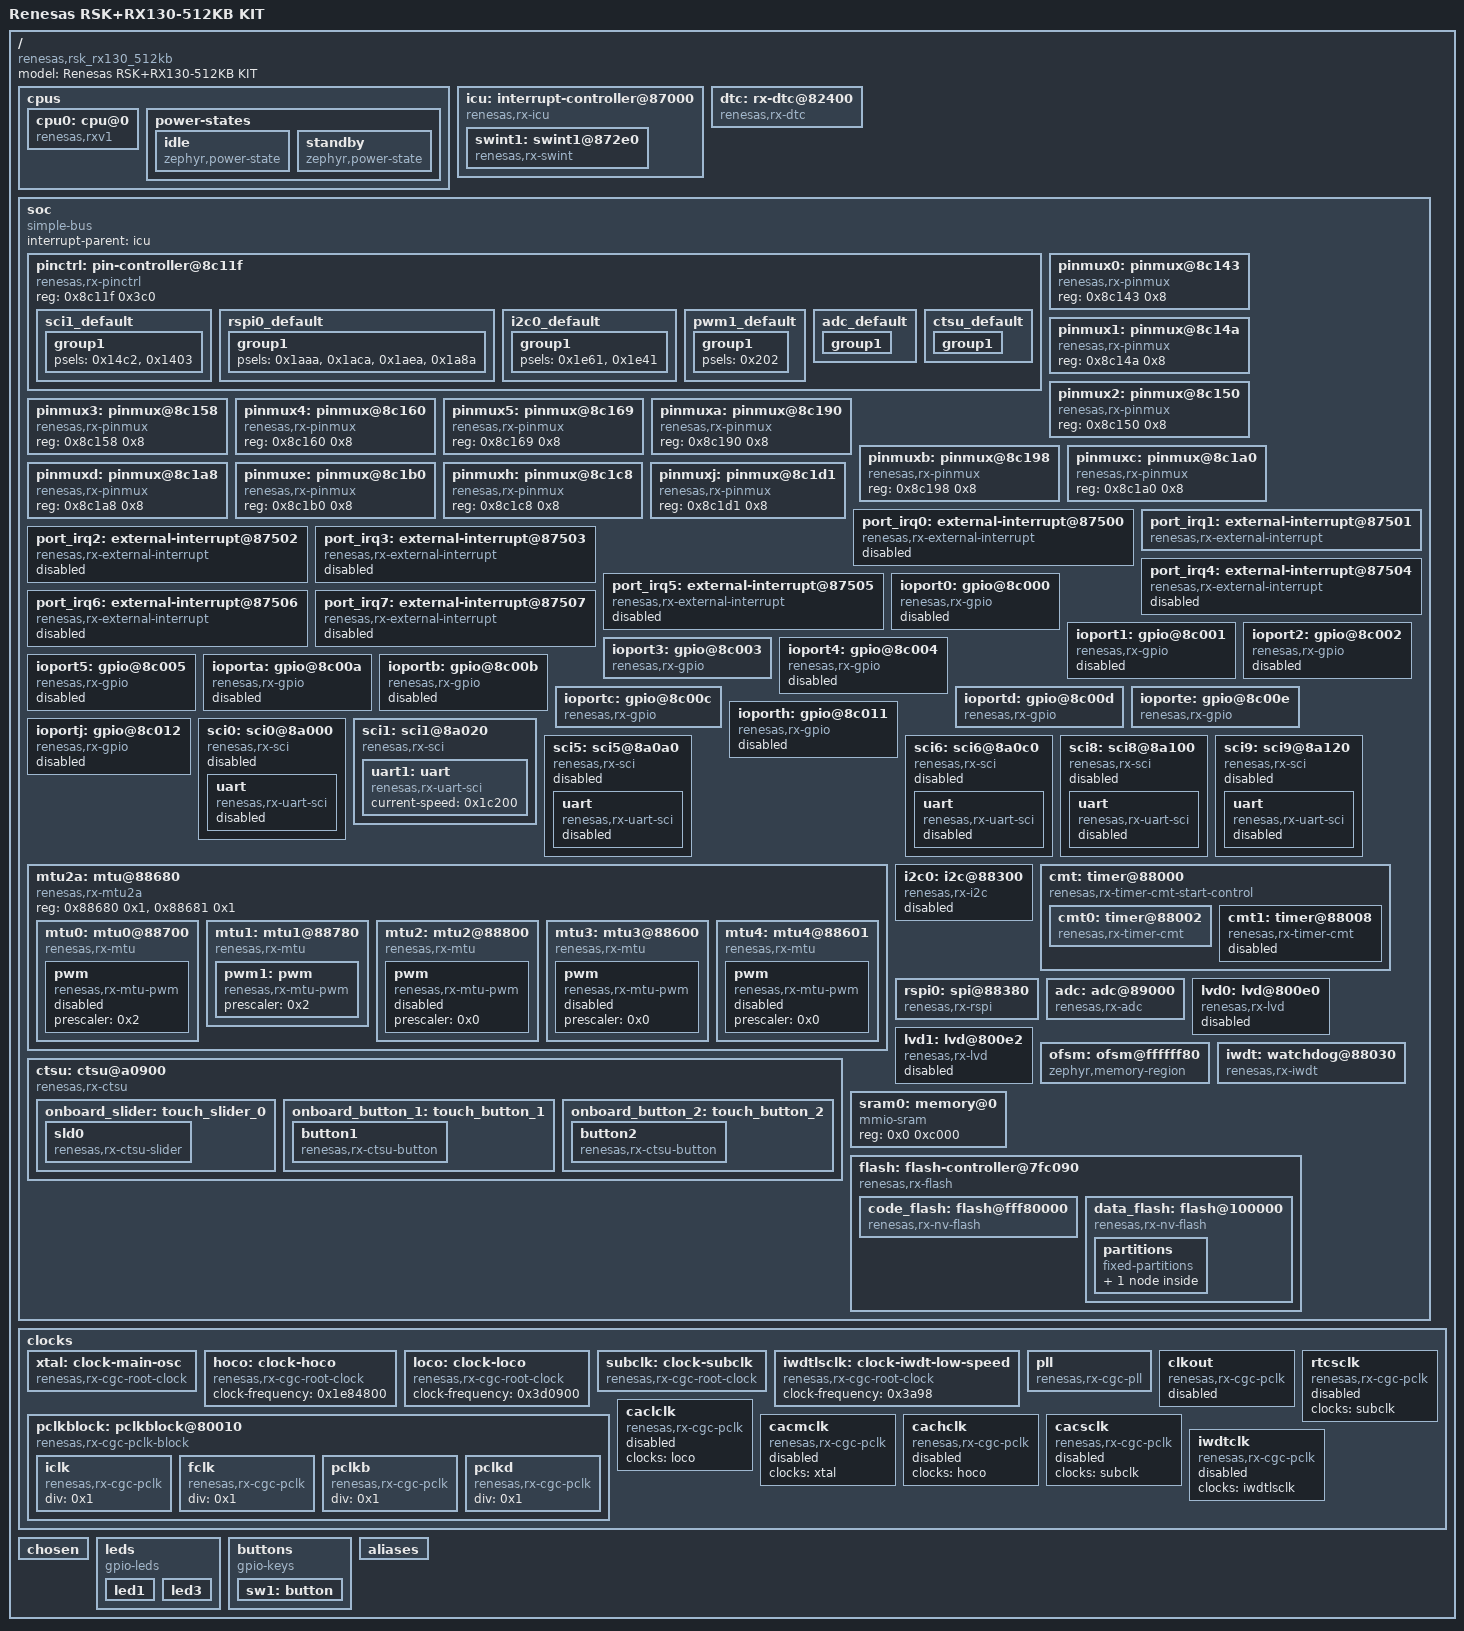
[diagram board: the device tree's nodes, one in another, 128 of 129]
/dts-v1/;

/* node '/' defined in zephyr/dts/rx/renesas/rx130-common.dtsi:16 */
/ {
	#address-cells = < 0x1 >;               /* in zephyr/dts/rx/renesas/rx130-common.dtsi:17 */
	#size-cells = < 0x1 >;                  /* in zephyr/dts/rx/renesas/rx130-common.dtsi:18 */
	model = "Renesas RSK+RX130-512KB KIT";  /* in zephyr/boards/renesas/rsk_rx130/rsk_rx130.dts:16 */
	compatible = "renesas,rsk_rx130_512kb"; /* in zephyr/boards/renesas/rsk_rx130/rsk_rx130.dts:17 */

	/* node '/cpus' defined in zephyr/dts/rx/renesas/rx130-common.dtsi:20 */
	cpus {
		#address-cells = < 0x1 >; /* in zephyr/dts/rx/renesas/rx130-common.dtsi:21 */
		#size-cells = < 0x0 >;    /* in zephyr/dts/rx/renesas/rx130-common.dtsi:22 */

		/* node '/cpus/cpu@0' defined in zephyr/dts/rx/renesas/rx130-common.dtsi:24 */
		cpu0: cpu@0 {
			compatible = "renesas,rxv1";           /* in zephyr/dts/rx/renesas/rx130-common.dtsi:25 */
			device_type = "cpu";                   /* in zephyr/dts/rx/renesas/rx130-common.dtsi:26 */
			reg = < 0x0 >;                         /* in zephyr/dts/rx/renesas/rx130-common.dtsi:27 */
			cpu-power-states = < &idle &standby >; /* in zephyr/dts/rx/renesas/rx130-common.dtsi:28 */
			status = "okay";                       /* in zephyr/dts/rx/renesas/rx130-common.dtsi:29 */
		};

		/* node '/cpus/power-states' defined in zephyr/dts/rx/renesas/rx130-common.dtsi:32 */
		power-states {

			/* node '/cpus/power-states/idle' defined in zephyr/dts/rx/renesas/rx130-common.dtsi:33 */
			idle: idle {
				compatible = "zephyr,power-state";    /* in zephyr/dts/rx/renesas/rx130-common.dtsi:34 */
				power-state-name = "suspend-to-idle"; /* in zephyr/dts/rx/renesas/rx130-common.dtsi:35 */
				min-residency-us = < 0x12c >;         /* in zephyr/dts/rx/renesas/rx130-common.dtsi:36 */
				phandle = < 0x1 >;                    /* in zephyr/dts/rx/renesas/rx130-common.dtsi:28 */
			};

			/* node '/cpus/power-states/standby' defined in zephyr/dts/rx/renesas/rx130-common.dtsi:39 */
			standby: standby {
				compatible = "zephyr,power-state"; /* in zephyr/dts/rx/renesas/rx130-common.dtsi:40 */
				power-state-name = "standby";      /* in zephyr/dts/rx/renesas/rx130-common.dtsi:41 */
				min-residency-us = < 0xbb8 >;      /* in zephyr/dts/rx/renesas/rx130-common.dtsi:42 */
				exit-latency-us = < 0x1f4 >;       /* in zephyr/dts/rx/renesas/rx130-common.dtsi:43 */
				phandle = < 0x2 >;                 /* in zephyr/dts/rx/renesas/rx130-common.dtsi:28 */
			};
		};
	};

	/* node '/interrupt-controller@87000' defined in zephyr/dts/rx/renesas/rx130-common.dtsi:48 */
	icu: interrupt-controller@87000 {
		#interrupt-cells = < 0x2 >;    /* in zephyr/dts/rx/renesas/rx130-common.dtsi:49 */
		#address-cells = < 0x1 >;      /* in zephyr/dts/rx/renesas/rx130-common.dtsi:50 */
		#size-cells = < 0x1 >;         /* in zephyr/dts/rx/renesas/rx130-common.dtsi:51 */
		compatible = "renesas,rx-icu"; /* in zephyr/dts/rx/renesas/rx130-common.dtsi:52 */
		interrupt-controller;          /* in zephyr/dts/rx/renesas/rx130-common.dtsi:53 */
		reg = < 0x87000 0xff >,
		      < 0x87200 0x1f >,
		      < 0x87300 0xff >,
		      < 0x872f0 0x2 >,
		      < 0x87500 0xf >,
		      < 0x87510 0x1 >,
		      < 0x87514 0x1 >,
		      < 0x87580 0x1 >,
		      < 0x87581 0x1 >,
		      < 0x87582 0x1 >;         /* in zephyr/dts/rx/renesas/rx130-common.dtsi:54 */
		reg-names = "IR",
		            "IER",
		            "IPR",
		            "FIR",
		            "IRQCR",
		            "IRQFLTE",
		            "IRQFLTC0",
		            "NMISR",
		            "NMIER",
		            "NMICLR";          /* in zephyr/dts/rx/renesas/rx130-common.dtsi:64 */
		phandle = < 0x3 >;             /* in zephyr/dts/rx/renesas/rx130-common.dtsi:71 */

		/* node '/interrupt-controller@87000/swint1@872e0' defined in zephyr/dts/rx/renesas/rx130-common.dtsi:67 */
		swint1: swint1@872e0 {
			compatible = "renesas,rx-swint"; /* in zephyr/dts/rx/renesas/rx130-common.dtsi:68 */
			reg = < 0x872e0 0x1 >;           /* in zephyr/dts/rx/renesas/rx130-common.dtsi:69 */
			interrupts = < 0x1b 0xe >;       /* in zephyr/dts/rx/renesas/rx130-common.dtsi:70 */
			interrupt-parent = < &icu >;     /* in zephyr/dts/rx/renesas/rx130-common.dtsi:71 */
			status = "okay";                 /* in zephyr/dts/rx/renesas/rx130-common.dtsi:72 */
		};
	};

	/* node '/rx-dtc@82400' defined in zephyr/dts/rx/renesas/rx130-common.dtsi:76 */
	dtc: rx-dtc@82400 {
		compatible = "renesas,rx-dtc"; /* in zephyr/dts/rx/renesas/rx130-common.dtsi:77 */
		reg = < 0x82400 0x1 >;         /* in zephyr/dts/rx/renesas/rx130-common.dtsi:78 */
		clocks = < &iclk 0x0 0x1c >;   /* in zephyr/dts/rx/renesas/rx130-common.dtsi:79 */
		status = "okay";               /* in zephyr/dts/rx/renesas/rx130-common.dtsi:80 */
		phandle = < 0x1b >;            /* in zephyr/dts/rx/renesas/rx130-common.dtsi:572 */
	};

	/* node '/soc' defined in zephyr/dts/rx/renesas/rx130-common.dtsi:83 */
	soc {
		#address-cells = < 0x1 >;    /* in zephyr/dts/rx/renesas/rx130-common.dtsi:84 */
		#size-cells = < 0x1 >;       /* in zephyr/dts/rx/renesas/rx130-common.dtsi:85 */
		device_type = "soc";         /* in zephyr/dts/rx/renesas/rx130-common.dtsi:86 */
		compatible = "simple-bus";   /* in zephyr/dts/rx/renesas/rx130-common.dtsi:87 */
		interrupt-parent = < &icu >; /* in zephyr/dts/rx/renesas/rx130-common.dtsi:88 */

		/* node '/soc/pin-controller@8c11f' defined in zephyr/dts/rx/renesas/rx130-common.dtsi:90 */
		pinctrl: pin-controller@8c11f {
			compatible = "renesas,rx-pinctrl"; /* in zephyr/dts/rx/renesas/rx130-common.dtsi:91 */
			reg = < 0x8c11f 0x3c0 >;           /* in zephyr/dts/rx/renesas/rx130-common.dtsi:92 */
			status = "okay";                   /* in zephyr/dts/rx/renesas/rx130-common.dtsi:93 */

			/* node '/soc/pin-controller@8c11f/sci1_default' defined in zephyr/boards/renesas/rsk_rx130/rsk_rx130_512kb-pinctrl.dtsi:8 */
			sci1_default: sci1_default {
				phandle = < 0x1c >; /* in zephyr/boards/renesas/rsk_rx130/rsk_rx130.dts:102 */

				/* node '/soc/pin-controller@8c11f/sci1_default/group1' defined in zephyr/boards/renesas/rsk_rx130/rsk_rx130_512kb-pinctrl.dtsi:9 */
				group1 {
					psels = < 0x14c2 >,
					        < 0x1403 >; /* in zephyr/boards/renesas/rsk_rx130/rsk_rx130_512kb-pinctrl.dtsi:10 */
				};
			};

			/* node '/soc/pin-controller@8c11f/rspi0_default' defined in zephyr/boards/renesas/rsk_rx130/rsk_rx130_512kb-pinctrl.dtsi:15 */
			rspi0_default: rspi0_default {
				phandle = < 0x1f >; /* in zephyr/boards/renesas/rsk_rx130/rsk_rx130.dts:113 */

				/* node '/soc/pin-controller@8c11f/rspi0_default/group1' defined in zephyr/boards/renesas/rsk_rx130/rsk_rx130_512kb-pinctrl.dtsi:16 */
				group1 {
					psels = < 0x1aaa >,
					        < 0x1aca >,
					        < 0x1aea >,
					        < 0x1a8a >; /* in zephyr/boards/renesas/rsk_rx130/rsk_rx130_512kb-pinctrl.dtsi:17 */
				};
			};

			/* node '/soc/pin-controller@8c11f/i2c0_default' defined in zephyr/boards/renesas/rsk_rx130/rsk_rx130_512kb-pinctrl.dtsi:24 */
			i2c0_default: i2c0_default {
				phandle = < 0x1e >; /* in zephyr/boards/renesas/rsk_rx130/rsk_rx130.dts:120 */

				/* node '/soc/pin-controller@8c11f/i2c0_default/group1' defined in zephyr/boards/renesas/rsk_rx130/rsk_rx130_512kb-pinctrl.dtsi:25 */
				group1 {
					psels = < 0x1e61 >,
					        < 0x1e41 >; /* in zephyr/boards/renesas/rsk_rx130/rsk_rx130_512kb-pinctrl.dtsi:26 */
				};
			};

			/* node '/soc/pin-controller@8c11f/pwm1_default' defined in zephyr/boards/renesas/rsk_rx130/rsk_rx130_512kb-pinctrl.dtsi:31 */
			pwm1_default: pwm1_default {
				phandle = < 0x1d >; /* in zephyr/boards/renesas/rsk_rx130/rsk_rx130.dts:183 */

				/* node '/soc/pin-controller@8c11f/pwm1_default/group1' defined in zephyr/boards/renesas/rsk_rx130/rsk_rx130_512kb-pinctrl.dtsi:32 */
				group1 {
					psels = < 0x202 >; /* in zephyr/boards/renesas/rsk_rx130/rsk_rx130_512kb-pinctrl.dtsi:33 */
				};
			};

			/* node '/soc/pin-controller@8c11f/adc_default' defined in zephyr/boards/renesas/rsk_rx130/rsk_rx130_512kb-pinctrl.dtsi:37 */
			adc_default: adc_default {
				phandle = < 0x20 >; /* in zephyr/boards/renesas/rsk_rx130/rsk_rx130.dts:205 */

				/* node '/soc/pin-controller@8c11f/adc_default/group1' defined in zephyr/boards/renesas/rsk_rx130/rsk_rx130_512kb-pinctrl.dtsi:38 */
				group1 {
					psels = < 0x24 >;      /* in zephyr/boards/renesas/rsk_rx130/rsk_rx130_512kb-pinctrl.dtsi:40 */
					renesas,analog-enable; /* in zephyr/boards/renesas/rsk_rx130/rsk_rx130_512kb-pinctrl.dtsi:41 */
				};
			};

			/* node '/soc/pin-controller@8c11f/ctsu_default' defined in zephyr/boards/renesas/rsk_rx130/rsk_rx130_512kb-pinctrl.dtsi:45 */
			ctsu_default: ctsu_default {
				phandle = < 0x21 >; /* in zephyr/boards/renesas/rsk_rx130/rsk_rx130.dts:126 */

				/* node '/soc/pin-controller@8c11f/ctsu_default/group1' defined in zephyr/boards/renesas/rsk_rx130/rsk_rx130_512kb-pinctrl.dtsi:46 */
				group1 {
					psels = < 0x3271 >,
					        < 0x3251 >,
					        < 0x3231 >,
					        < 0x3211 >,
					        < 0x32a5 >,
					        < 0x3285 >,
					        < 0x328c >; /* in zephyr/boards/renesas/rsk_rx130/rsk_rx130_512kb-pinctrl.dtsi:47 */
				};
			};
		};

		/* node '/soc/pinmux@8c143' defined in zephyr/dts/rx/renesas/rx130-common.dtsi:96 */
		pinmux0: pinmux@8c143 {
			compatible = "renesas,rx-pinmux"; /* in zephyr/dts/rx/renesas/rx130-common.dtsi:97 */
			#pinmux-cells = < 0x2 >;          /* in zephyr/dts/rx/renesas/rx130-common.dtsi:98 */
			reg = < 0x8c143 0x8 >;            /* in zephyr/dts/rx/renesas/rx130-common.dtsi:99 */
			status = "okay";                  /* in zephyr/dts/rx/renesas/rx130-common.dtsi:100 */
			phandle = < 0x5 >;                /* in zephyr/dts/rx/renesas/rx130-common.dtsi:279 */
		};

		/* node '/soc/pinmux@8c14a' defined in zephyr/dts/rx/renesas/rx130-common.dtsi:103 */
		pinmux1: pinmux@8c14a {
			compatible = "renesas,rx-pinmux"; /* in zephyr/dts/rx/renesas/rx130-common.dtsi:104 */
			#pinmux-cells = < 0x2 >;          /* in zephyr/dts/rx/renesas/rx130-common.dtsi:105 */
			reg = < 0x8c14a 0x8 >;            /* in zephyr/dts/rx/renesas/rx130-common.dtsi:106 */
			status = "okay";                  /* in zephyr/dts/rx/renesas/rx130-common.dtsi:107 */
			phandle = < 0x6 >;                /* in zephyr/dts/rx/renesas/rx130-common.dtsi:298 */
		};

		/* node '/soc/pinmux@8c150' defined in zephyr/dts/rx/renesas/rx130-common.dtsi:110 */
		pinmux2: pinmux@8c150 {
			compatible = "renesas,rx-pinmux"; /* in zephyr/dts/rx/renesas/rx130-common.dtsi:111 */
			#pinmux-cells = < 0x2 >;          /* in zephyr/dts/rx/renesas/rx130-common.dtsi:112 */
			reg = < 0x8c150 0x8 >;            /* in zephyr/dts/rx/renesas/rx130-common.dtsi:113 */
			status = "okay";                  /* in zephyr/dts/rx/renesas/rx130-common.dtsi:114 */
			phandle = < 0xd >;                /* in zephyr/dts/rx/renesas/rx130-common.dtsi:331 */
		};

		/* node '/soc/pinmux@8c158' defined in zephyr/dts/rx/renesas/rx130-common.dtsi:117 */
		pinmux3: pinmux@8c158 {
			compatible = "renesas,rx-pinmux"; /* in zephyr/dts/rx/renesas/rx130-common.dtsi:118 */
			#pinmux-cells = < 0x2 >;          /* in zephyr/dts/rx/renesas/rx130-common.dtsi:119 */
			reg = < 0x8c158 0x8 >;            /* in zephyr/dts/rx/renesas/rx130-common.dtsi:120 */
			status = "okay";                  /* in zephyr/dts/rx/renesas/rx130-common.dtsi:121 */
			phandle = < 0xe >;                /* in zephyr/dts/rx/renesas/rx130-common.dtsi:350 */
		};

		/* node '/soc/pinmux@8c160' defined in zephyr/dts/rx/renesas/rx130-common.dtsi:124 */
		pinmux4: pinmux@8c160 {
			compatible = "renesas,rx-pinmux"; /* in zephyr/dts/rx/renesas/rx130-common.dtsi:125 */
			#pinmux-cells = < 0x2 >;          /* in zephyr/dts/rx/renesas/rx130-common.dtsi:126 */
			reg = < 0x8c160 0x8 >;            /* in zephyr/dts/rx/renesas/rx130-common.dtsi:127 */
			status = "okay";                  /* in zephyr/dts/rx/renesas/rx130-common.dtsi:128 */
			phandle = < 0x11 >;               /* in zephyr/dts/rx/renesas/rx130-common.dtsi:377 */
		};

		/* node '/soc/pinmux@8c169' defined in zephyr/dts/rx/renesas/rx130-common.dtsi:131 */
		pinmux5: pinmux@8c169 {
			compatible = "renesas,rx-pinmux"; /* in zephyr/dts/rx/renesas/rx130-common.dtsi:132 */
			#pinmux-cells = < 0x2 >;          /* in zephyr/dts/rx/renesas/rx130-common.dtsi:133 */
			reg = < 0x8c169 0x8 >;            /* in zephyr/dts/rx/renesas/rx130-common.dtsi:134 */
			status = "okay";                  /* in zephyr/dts/rx/renesas/rx130-common.dtsi:135 */
			phandle = < 0x12 >;               /* in zephyr/dts/rx/renesas/rx130-common.dtsi:394 */
		};

		/* node '/soc/pinmux@8c190' defined in zephyr/dts/rx/renesas/rx130-common.dtsi:138 */
		pinmuxa: pinmux@8c190 {
			compatible = "renesas,rx-pinmux"; /* in zephyr/dts/rx/renesas/rx130-common.dtsi:139 */
			#pinmux-cells = < 0x2 >;          /* in zephyr/dts/rx/renesas/rx130-common.dtsi:140 */
			reg = < 0x8c190 0x8 >;            /* in zephyr/dts/rx/renesas/rx130-common.dtsi:141 */
			status = "okay";                  /* in zephyr/dts/rx/renesas/rx130-common.dtsi:142 */
			phandle = < 0x13 >;               /* in zephyr/dts/rx/renesas/rx130-common.dtsi:413 */
		};

		/* node '/soc/pinmux@8c198' defined in zephyr/dts/rx/renesas/rx130-common.dtsi:145 */
		pinmuxb: pinmux@8c198 {
			compatible = "renesas,rx-pinmux"; /* in zephyr/dts/rx/renesas/rx130-common.dtsi:146 */
			#pinmux-cells = < 0x2 >;          /* in zephyr/dts/rx/renesas/rx130-common.dtsi:147 */
			reg = < 0x8c198 0x8 >;            /* in zephyr/dts/rx/renesas/rx130-common.dtsi:148 */
			status = "okay";                  /* in zephyr/dts/rx/renesas/rx130-common.dtsi:149 */
			phandle = < 0x14 >;               /* in zephyr/dts/rx/renesas/rx130-common.dtsi:437 */
		};

		/* node '/soc/pinmux@8c1a0' defined in zephyr/dts/rx/renesas/rx130-common.dtsi:152 */
		pinmuxc: pinmux@8c1a0 {
			compatible = "renesas,rx-pinmux"; /* in zephyr/dts/rx/renesas/rx130-common.dtsi:153 */
			#pinmux-cells = < 0x2 >;          /* in zephyr/dts/rx/renesas/rx130-common.dtsi:154 */
			reg = < 0x8c1a0 0x8 >;            /* in zephyr/dts/rx/renesas/rx130-common.dtsi:155 */
			status = "okay";                  /* in zephyr/dts/rx/renesas/rx130-common.dtsi:156 */
			phandle = < 0x15 >;               /* in zephyr/dts/rx/renesas/rx130-common.dtsi:459 */
		};

		/* node '/soc/pinmux@8c1a8' defined in zephyr/dts/rx/renesas/rx130-common.dtsi:159 */
		pinmuxd: pinmux@8c1a8 {
			compatible = "renesas,rx-pinmux"; /* in zephyr/dts/rx/renesas/rx130-common.dtsi:160 */
			#pinmux-cells = < 0x2 >;          /* in zephyr/dts/rx/renesas/rx130-common.dtsi:161 */
			reg = < 0x8c1a8 0x8 >;            /* in zephyr/dts/rx/renesas/rx130-common.dtsi:162 */
			status = "okay";                  /* in zephyr/dts/rx/renesas/rx130-common.dtsi:163 */
			phandle = < 0x16 >;               /* in zephyr/dts/rx/renesas/rx130-common.dtsi:477 */
		};

		/* node '/soc/pinmux@8c1b0' defined in zephyr/dts/rx/renesas/rx130-common.dtsi:166 */
		pinmuxe: pinmux@8c1b0 {
			compatible = "renesas,rx-pinmux"; /* in zephyr/dts/rx/renesas/rx130-common.dtsi:167 */
			#pinmux-cells = < 0x2 >;          /* in zephyr/dts/rx/renesas/rx130-common.dtsi:168 */
			reg = < 0x8c1b0 0x8 >;            /* in zephyr/dts/rx/renesas/rx130-common.dtsi:169 */
			status = "okay";                  /* in zephyr/dts/rx/renesas/rx130-common.dtsi:170 */
			phandle = < 0x17 >;               /* in zephyr/dts/rx/renesas/rx130-common.dtsi:514 */
		};

		/* node '/soc/pinmux@8c1c8' defined in zephyr/dts/rx/renesas/rx130-common.dtsi:173 */
		pinmuxh: pinmux@8c1c8 {
			compatible = "renesas,rx-pinmux"; /* in zephyr/dts/rx/renesas/rx130-common.dtsi:174 */
			#pinmux-cells = < 0x2 >;          /* in zephyr/dts/rx/renesas/rx130-common.dtsi:175 */
			reg = < 0x8c1c8 0x8 >;            /* in zephyr/dts/rx/renesas/rx130-common.dtsi:176 */
			status = "okay";                  /* in zephyr/dts/rx/renesas/rx130-common.dtsi:177 */
			phandle = < 0x18 >;               /* in zephyr/dts/rx/renesas/rx130-common.dtsi:538 */
		};

		/* node '/soc/pinmux@8c1d1' defined in zephyr/dts/rx/renesas/rx130-common.dtsi:180 */
		pinmuxj: pinmux@8c1d1 {
			compatible = "renesas,rx-pinmux"; /* in zephyr/dts/rx/renesas/rx130-common.dtsi:181 */
			#pinmux-cells = < 0x2 >;          /* in zephyr/dts/rx/renesas/rx130-common.dtsi:182 */
			reg = < 0x8c1d1 0x8 >;            /* in zephyr/dts/rx/renesas/rx130-common.dtsi:183 */
			status = "okay";                  /* in zephyr/dts/rx/renesas/rx130-common.dtsi:184 */
			phandle = < 0x19 >;               /* in zephyr/dts/rx/renesas/rx130-common.dtsi:561 */
		};

		/* node '/soc/external-interrupt@87500' defined in zephyr/dts/rx/renesas/rx130-common.dtsi:187 */
		port_irq0: external-interrupt@87500 {
			compatible = "renesas,rx-external-interrupt"; /* in zephyr/dts/rx/renesas/rx130-common.dtsi:188 */
			reg = < 0x87500 0x1 >;                        /* in zephyr/dts/rx/renesas/rx130-common.dtsi:189 */
			interrupts = < 0x40 0xc >;                    /* in zephyr/dts/rx/renesas/rx130-common.dtsi:190 */
			channel = < 0x0 >;                            /* in zephyr/dts/rx/renesas/rx130-common.dtsi:191 */
			renesas,sample-clock-div = < 0x40 >;          /* in zephyr/dts/rx/renesas/rx130-common.dtsi:192 */
			#port-irq-cells = < 0x0 >;                    /* in zephyr/dts/rx/renesas/rx130-common.dtsi:193 */
			status = "disabled";                          /* in zephyr/dts/rx/renesas/rx130-common.dtsi:194 */
			phandle = < 0xf >;                            /* in zephyr/dts/rx/renesas/rx130-common.dtsi:351 */
		};

		/* node '/soc/external-interrupt@87501' defined in zephyr/dts/rx/renesas/rx130-common.dtsi:197 */
		port_irq1: external-interrupt@87501 {
			compatible = "renesas,rx-external-interrupt"; /* in zephyr/dts/rx/renesas/rx130-common.dtsi:198 */
			reg = < 0x87501 0x1 >;                        /* in zephyr/dts/rx/renesas/rx130-common.dtsi:199 */
			interrupts = < 0x41 0xc >;                    /* in zephyr/dts/rx/renesas/rx130-common.dtsi:200 */
			channel = < 0x1 >;                            /* in zephyr/dts/rx/renesas/rx130-common.dtsi:201 */
			renesas,sample-clock-div = < 0x40 >;          /* in zephyr/dts/rx/renesas/rx130-common.dtsi:202 */
			#port-irq-cells = < 0x0 >;                    /* in zephyr/dts/rx/renesas/rx130-common.dtsi:203 */
			status = "okay";                              /* in zephyr/boards/renesas/rsk_rx130/rsk_rx130.dts:178 */
			phandle = < 0x10 >;                           /* in zephyr/dts/rx/renesas/rx130-common.dtsi:351 */
		};

		/* node '/soc/external-interrupt@87502' defined in zephyr/dts/rx/renesas/rx130-common.dtsi:207 */
		port_irq2: external-interrupt@87502 {
			compatible = "renesas,rx-external-interrupt"; /* in zephyr/dts/rx/renesas/rx130-common.dtsi:208 */
			reg = < 0x87502 0x1 >;                        /* in zephyr/dts/rx/renesas/rx130-common.dtsi:209 */
			interrupts = < 0x42 0xc >;                    /* in zephyr/dts/rx/renesas/rx130-common.dtsi:210 */
			channel = < 0x2 >;                            /* in zephyr/dts/rx/renesas/rx130-common.dtsi:211 */
			renesas,sample-clock-div = < 0x40 >;          /* in zephyr/dts/rx/renesas/rx130-common.dtsi:212 */
			#port-irq-cells = < 0x0 >;                    /* in zephyr/dts/rx/renesas/rx130-common.dtsi:213 */
			status = "disabled";                          /* in zephyr/dts/rx/renesas/rx130-common.dtsi:214 */
			phandle = < 0x7 >;                            /* in zephyr/dts/rx/renesas/rx130-common.dtsi:299 */
		};

		/* node '/soc/external-interrupt@87503' defined in zephyr/dts/rx/renesas/rx130-common.dtsi:217 */
		port_irq3: external-interrupt@87503 {
			compatible = "renesas,rx-external-interrupt"; /* in zephyr/dts/rx/renesas/rx130-common.dtsi:218 */
			reg = < 0x87503 0x1 >;                        /* in zephyr/dts/rx/renesas/rx130-common.dtsi:219 */
			interrupts = < 0x43 0xc >;                    /* in zephyr/dts/rx/renesas/rx130-common.dtsi:220 */
			channel = < 0x3 >;                            /* in zephyr/dts/rx/renesas/rx130-common.dtsi:221 */
			renesas,sample-clock-div = < 0x40 >;          /* in zephyr/dts/rx/renesas/rx130-common.dtsi:222 */
			#port-irq-cells = < 0x0 >;                    /* in zephyr/dts/rx/renesas/rx130-common.dtsi:223 */
			status = "disabled";                          /* in zephyr/dts/rx/renesas/rx130-common.dtsi:224 */
			phandle = < 0x8 >;                            /* in zephyr/dts/rx/renesas/rx130-common.dtsi:299 */
		};

		/* node '/soc/external-interrupt@87504' defined in zephyr/dts/rx/renesas/rx130-common.dtsi:227 */
		port_irq4: external-interrupt@87504 {
			compatible = "renesas,rx-external-interrupt"; /* in zephyr/dts/rx/renesas/rx130-common.dtsi:228 */
			reg = < 0x87504 0x1 >;                        /* in zephyr/dts/rx/renesas/rx130-common.dtsi:229 */
			interrupts = < 0x44 0xc >;                    /* in zephyr/dts/rx/renesas/rx130-common.dtsi:230 */
			channel = < 0x4 >;                            /* in zephyr/dts/rx/renesas/rx130-common.dtsi:231 */
			renesas,sample-clock-div = < 0x40 >;          /* in zephyr/dts/rx/renesas/rx130-common.dtsi:232 */
			#port-irq-cells = < 0x0 >;                    /* in zephyr/dts/rx/renesas/rx130-common.dtsi:233 */
			status = "disabled";                          /* in zephyr/dts/rx/renesas/rx130-common.dtsi:234 */
			phandle = < 0x9 >;                            /* in zephyr/dts/rx/renesas/rx130-common.dtsi:299 */
		};

		/* node '/soc/external-interrupt@87505' defined in zephyr/dts/rx/renesas/rx130-common.dtsi:237 */
		port_irq5: external-interrupt@87505 {
			compatible = "renesas,rx-external-interrupt"; /* in zephyr/dts/rx/renesas/rx130-common.dtsi:238 */
			reg = < 0x87505 0x1 >;                        /* in zephyr/dts/rx/renesas/rx130-common.dtsi:239 */
			interrupts = < 0x45 0xc >;                    /* in zephyr/dts/rx/renesas/rx130-common.dtsi:240 */
			channel = < 0x5 >;                            /* in zephyr/dts/rx/renesas/rx130-common.dtsi:241 */
			renesas,sample-clock-div = < 0x40 >;          /* in zephyr/dts/rx/renesas/rx130-common.dtsi:242 */
			#port-irq-cells = < 0x0 >;                    /* in zephyr/dts/rx/renesas/rx130-common.dtsi:243 */
			status = "disabled";                          /* in zephyr/dts/rx/renesas/rx130-common.dtsi:244 */
			phandle = < 0xa >;                            /* in zephyr/dts/rx/renesas/rx130-common.dtsi:299 */
		};

		/* node '/soc/external-interrupt@87506' defined in zephyr/dts/rx/renesas/rx130-common.dtsi:247 */
		port_irq6: external-interrupt@87506 {
			compatible = "renesas,rx-external-interrupt"; /* in zephyr/dts/rx/renesas/rx130-common.dtsi:248 */
			reg = < 0x87506 0x1 >;                        /* in zephyr/dts/rx/renesas/rx130-common.dtsi:249 */
			interrupts = < 0x46 0xc >;                    /* in zephyr/dts/rx/renesas/rx130-common.dtsi:250 */
			channel = < 0x6 >;                            /* in zephyr/dts/rx/renesas/rx130-common.dtsi:251 */
			renesas,sample-clock-div = < 0x40 >;          /* in zephyr/dts/rx/renesas/rx130-common.dtsi:252 */
			#port-irq-cells = < 0x0 >;                    /* in zephyr/dts/rx/renesas/rx130-common.dtsi:253 */
			status = "disabled";                          /* in zephyr/dts/rx/renesas/rx130-common.dtsi:254 */
			phandle = < 0xb >;                            /* in zephyr/dts/rx/renesas/rx130-common.dtsi:299 */
		};

		/* node '/soc/external-interrupt@87507' defined in zephyr/dts/rx/renesas/rx130-common.dtsi:257 */
		port_irq7: external-interrupt@87507 {
			compatible = "renesas,rx-external-interrupt"; /* in zephyr/dts/rx/renesas/rx130-common.dtsi:258 */
			reg = < 0x87507 0x1 >;                        /* in zephyr/dts/rx/renesas/rx130-common.dtsi:259 */
			interrupts = < 0x47 0xc >;                    /* in zephyr/dts/rx/renesas/rx130-common.dtsi:260 */
			channel = < 0x7 >;                            /* in zephyr/dts/rx/renesas/rx130-common.dtsi:261 */
			renesas,sample-clock-div = < 0x40 >;          /* in zephyr/dts/rx/renesas/rx130-common.dtsi:262 */
			#port-irq-cells = < 0x0 >;                    /* in zephyr/dts/rx/renesas/rx130-common.dtsi:263 */
			status = "disabled";                          /* in zephyr/dts/rx/renesas/rx130-common.dtsi:264 */
			phandle = < 0xc >;                            /* in zephyr/dts/rx/renesas/rx130-common.dtsi:299 */
		};

		/* node '/soc/gpio@8c000' defined in zephyr/dts/rx/renesas/rx130-common.dtsi:267 */
		ioport0: gpio@8c000 {
			compatible = "renesas,rx-gpio"; /* in zephyr/dts/rx/renesas/rx130-common.dtsi:268 */
			gpio-controller;                /* in zephyr/dts/rx/renesas/rx130-common.dtsi:269 */
			#gpio-cells = < 0x2 >;          /* in zephyr/dts/rx/renesas/rx130-common.dtsi:270 */
			ngpios = < 0x8 >;               /* in zephyr/dts/rx/renesas/rx130-common.dtsi:271 */
			port = < 0x0 >;                 /* in zephyr/dts/rx/renesas/rx130-common.dtsi:272 */
			reg = < 0x8c000 0x1 >,
			      < 0x8c020 0x1 >,
			      < 0x8c040 0x1 >,
			      < 0x8c060 0x1 >,
			      < 0x8c0c0 0x1 >;          /* in zephyr/dts/rx/renesas/rx130-common.dtsi:273 */
			reg-names = "PDR",
			            "PODR",
			            "PIDR",
			            "PMR",
			            "PCR";              /* in zephyr/dts/rx/renesas/rx130-common.dtsi:278 */
			pinmux = < &pinmux0 >;          /* in zephyr/dts/rx/renesas/rx130-common.dtsi:279 */
			status = "disabled";            /* in zephyr/dts/rx/renesas/rx130-common.dtsi:280 */
		};

		/* node '/soc/gpio@8c001' defined in zephyr/dts/rx/renesas/rx130-common.dtsi:283 */
		ioport1: gpio@8c001 {
			compatible = "renesas,rx-gpio";                                                    /* in zephyr/dts/rx/renesas/rx130-common.dtsi:284 */
			gpio-controller;                                                                   /* in zephyr/dts/rx/renesas/rx130-common.dtsi:285 */
			#gpio-cells = < 0x2 >;                                                             /* in zephyr/dts/rx/renesas/rx130-common.dtsi:286 */
			ngpios = < 0x8 >;                                                                  /* in zephyr/dts/rx/renesas/rx130-common.dtsi:287 */
			port = < 0x1 >;                                                                    /* in zephyr/dts/rx/renesas/rx130-common.dtsi:288 */
			reg = < 0x8c001 0x1 >,
			      < 0x8c021 0x1 >,
			      < 0x8c041 0x1 >,
			      < 0x8c061 0x1 >,
			      < 0x8c082 0x1 >,
			      < 0x8c083 0x1 >,
			      < 0x8c0c1 0x1 >,
			      < 0x8c0e1 0x1 >;                                                             /* in zephyr/dts/rx/renesas/rx130-common.dtsi:289 */
			reg-names = "PDR",
			            "PODR",
			            "PIDR",
			            "PMR",
			            "ODR0",
			            "ODR1",
			            "PCR",
			            "DSCR";                                                                /* in zephyr/dts/rx/renesas/rx130-common.dtsi:297 */
			pinmux = < &pinmux1 >;                                                             /* in zephyr/dts/rx/renesas/rx130-common.dtsi:298 */
			port-irqs = < &port_irq2 &port_irq3 &port_irq4 &port_irq5 &port_irq6 &port_irq7 >; /* in zephyr/dts/rx/renesas/rx130-common.dtsi:299 */
			port-irq-names = "port-irq2",
			                 "port-irq3",
			                 "port-irq4",
			                 "port-irq5",
			                 "port-irq6",
			                 "port-irq7";                                                      /* in zephyr/dts/rx/renesas/rx130-common.dtsi:301 */
			port-irq2-pins = < 0x2 >;                                                          /* in zephyr/dts/rx/renesas/rx130-common.dtsi:307 */
			port-irq3-pins = < 0x3 >;                                                          /* in zephyr/dts/rx/renesas/rx130-common.dtsi:308 */
			port-irq4-pins = < 0x4 >;                                                          /* in zephyr/dts/rx/renesas/rx130-common.dtsi:309 */
			port-irq5-pins = < 0x5 >;                                                          /* in zephyr/dts/rx/renesas/rx130-common.dtsi:310 */
			port-irq6-pins = < 0x6 >;                                                          /* in zephyr/dts/rx/renesas/rx130-common.dtsi:311 */
			port-irq7-pins = < 0x7 >;                                                          /* in zephyr/dts/rx/renesas/rx130-common.dtsi:312 */
			status = "disabled";                                                               /* in zephyr/dts/rx/renesas/rx130-common.dtsi:313 */
		};

		/* node '/soc/gpio@8c002' defined in zephyr/dts/rx/renesas/rx130-common.dtsi:316 */
		ioport2: gpio@8c002 {
			compatible = "renesas,rx-gpio"; /* in zephyr/dts/rx/renesas/rx130-common.dtsi:317 */
			gpio-controller;                /* in zephyr/dts/rx/renesas/rx130-common.dtsi:318 */
			#gpio-cells = < 0x2 >;          /* in zephyr/dts/rx/renesas/rx130-common.dtsi:319 */
			ngpios = < 0x8 >;               /* in zephyr/dts/rx/renesas/rx130-common.dtsi:320 */
			port = < 0x2 >;                 /* in zephyr/dts/rx/renesas/rx130-common.dtsi:321 */
			reg = < 0x8c002 0x1 >,
			      < 0x8c022 0x1 >,
			      < 0x8c042 0x1 >,
			      < 0x8c062 0x1 >,
			      < 0x8c084 0x1 >,
			      < 0x8c085 0x1 >,
			      < 0x8c0c2 0x1 >,
			      < 0x8c0e2 0x1 >;          /* in zephyr/dts/rx/renesas/rx130-common.dtsi:322 */
			reg-names = "PDR",
			            "PODR",
			            "PIDR",
			            "PMR",
			            "ODR0",
			            "ODR1",
			            "PCR",
			            "DSCR";             /* in zephyr/dts/rx/renesas/rx130-common.dtsi:330 */
			pinmux = < &pinmux2 >;          /* in zephyr/dts/rx/renesas/rx130-common.dtsi:331 */
			status = "disabled";            /* in zephyr/dts/rx/renesas/rx130-common.dtsi:332 */
		};

		/* node '/soc/gpio@8c003' defined in zephyr/dts/rx/renesas/rx130-common.dtsi:335 */
		ioport3: gpio@8c003 {
			compatible = "renesas,rx-gpio";                                         /* in zephyr/dts/rx/renesas/rx130-common.dtsi:336 */
			gpio-controller;                                                        /* in zephyr/dts/rx/renesas/rx130-common.dtsi:337 */
			#gpio-cells = < 0x2 >;                                                  /* in zephyr/dts/rx/renesas/rx130-common.dtsi:338 */
			ngpios = < 0x8 >;                                                       /* in zephyr/dts/rx/renesas/rx130-common.dtsi:339 */
			port = < 0x3 >;                                                         /* in zephyr/dts/rx/renesas/rx130-common.dtsi:340 */
			reg = < 0x8c003 0x1 >,
			      < 0x8c023 0x1 >,
			      < 0x8c043 0x1 >,
			      < 0x8c063 0x1 >,
			      < 0x8c086 0x1 >,
			      < 0x8c087 0x1 >,
			      < 0x8c0c3 0x1 >,
			      < 0x8c0e3 0x1 >;                                                  /* in zephyr/dts/rx/renesas/rx130-common.dtsi:341 */
			reg-names = "PDR",
			            "PODR",
			            "PIDR",
			            "PMR",
			            "ODR0",
			            "ODR1",
			            "PCR",
			            "DSCR";                                                     /* in zephyr/dts/rx/renesas/rx130-common.dtsi:349 */
			pinmux = < &pinmux3 >;                                                  /* in zephyr/dts/rx/renesas/rx130-common.dtsi:350 */
			port-irqs = < &port_irq0 &port_irq1 &port_irq2 &port_irq3 &port_irq4 >; /* in zephyr/dts/rx/renesas/rx130-common.dtsi:351 */
			port-irq-names = "port-irq0",
			                 "port-irq1",
			                 "port-irq2",
			                 "port-irq3",
			                 "port-irq4";                                           /* in zephyr/dts/rx/renesas/rx130-common.dtsi:352 */
			port-irq0-pins = < 0x0 >;                                               /* in zephyr/dts/rx/renesas/rx130-common.dtsi:357 */
			port-irq1-pins = < 0x1 >;                                               /* in zephyr/dts/rx/renesas/rx130-common.dtsi:358 */
			port-irq2-pins = < 0x2 >;                                               /* in zephyr/dts/rx/renesas/rx130-common.dtsi:359 */
			port-irq3-pins = < 0x3 >;                                               /* in zephyr/dts/rx/renesas/rx130-common.dtsi:360 */
			port-irq4-pins = < 0x4 >;                                               /* in zephyr/dts/rx/renesas/rx130-common.dtsi:361 */
			status = "okay";                                                        /* in zephyr/boards/renesas/rsk_rx130/rsk_rx130.dts:86 */
			phandle = < 0x2b >;                                                     /* in zephyr/boards/renesas/rsk_rx130/rsk_rx130.dts:46 */
		};

		/* node '/soc/gpio@8c004' defined in zephyr/dts/rx/renesas/rx130-common.dtsi:365 */
		ioport4: gpio@8c004 {
			compatible = "renesas,rx-gpio"; /* in zephyr/dts/rx/renesas/rx130-common.dtsi:366 */
			gpio-controller;                /* in zephyr/dts/rx/renesas/rx130-common.dtsi:367 */
			#gpio-cells = < 0x2 >;          /* in zephyr/dts/rx/renesas/rx130-common.dtsi:368 */
			ngpios = < 0x8 >;               /* in zephyr/dts/rx/renesas/rx130-common.dtsi:369 */
			port = < 0x4 >;                 /* in zephyr/dts/rx/renesas/rx130-common.dtsi:370 */
			reg = < 0x8c004 0x1 >,
			      < 0x8c024 0x1 >,
			      < 0x8c044 0x1 >,
			      < 0x8c064 0x1 >,
			      < 0x8c0c4 0x1 >;          /* in zephyr/dts/rx/renesas/rx130-common.dtsi:371 */
			reg-names = "PDR",
			            "PODR",
			            "PIDR",
			            "PMR",
			            "PCR";              /* in zephyr/dts/rx/renesas/rx130-common.dtsi:376 */
			pinmux = < &pinmux4 >;          /* in zephyr/dts/rx/renesas/rx130-common.dtsi:377 */
			status = "disabled";            /* in zephyr/dts/rx/renesas/rx130-common.dtsi:378 */
		};

		/* node '/soc/gpio@8c005' defined in zephyr/dts/rx/renesas/rx130-common.dtsi:381 */
		ioport5: gpio@8c005 {
			compatible = "renesas,rx-gpio"; /* in zephyr/dts/rx/renesas/rx130-common.dtsi:382 */
			gpio-controller;                /* in zephyr/dts/rx/renesas/rx130-common.dtsi:383 */
			#gpio-cells = < 0x2 >;          /* in zephyr/dts/rx/renesas/rx130-common.dtsi:384 */
			ngpios = < 0x8 >;               /* in zephyr/dts/rx/renesas/rx130-common.dtsi:385 */
			port = < 0x5 >;                 /* in zephyr/dts/rx/renesas/rx130-common.dtsi:386 */
			reg = < 0x8c005 0x1 >,
			      < 0x8c025 0x1 >,
			      < 0x8c045 0x1 >,
			      < 0x8c065 0x1 >,
			      < 0x8c0c5 0x1 >,
			      < 0x8c0e5 0x1 >;          /* in zephyr/dts/rx/renesas/rx130-common.dtsi:387 */
			reg-names = "PDR",
			            "PODR",
			            "PIDR",
			            "PMR",
			            "PCR",
			            "DSCR";             /* in zephyr/dts/rx/renesas/rx130-common.dtsi:393 */
			pinmux = < &pinmux5 >;          /* in zephyr/dts/rx/renesas/rx130-common.dtsi:394 */
			status = "disabled";            /* in zephyr/dts/rx/renesas/rx130-common.dtsi:395 */
		};

		/* node '/soc/gpio@8c00a' defined in zephyr/dts/rx/renesas/rx130-common.dtsi:398 */
		ioporta: gpio@8c00a {
			compatible = "renesas,rx-gpio";        /* in zephyr/dts/rx/renesas/rx130-common.dtsi:399 */
			gpio-controller;                       /* in zephyr/dts/rx/renesas/rx130-common.dtsi:400 */
			#gpio-cells = < 0x2 >;                 /* in zephyr/dts/rx/renesas/rx130-common.dtsi:401 */
			ngpios = < 0x8 >;                      /* in zephyr/dts/rx/renesas/rx130-common.dtsi:402 */
			port = < 0xa >;                        /* in zephyr/dts/rx/renesas/rx130-common.dtsi:403 */
			reg = < 0x8c00a 0x1 >,
			      < 0x8c02a 0x1 >,
			      < 0x8c04a 0x1 >,
			      < 0x8c06a 0x1 >,
			      < 0x8c094 0x1 >,
			      < 0x8c095 0x1 >,
			      < 0x8c0ca 0x1 >,
			      < 0x8c0ea 0x1 >;                 /* in zephyr/dts/rx/renesas/rx130-common.dtsi:404 */
			reg-names = "PDR",
			            "PODR",
			            "PIDR",
			            "PMR",
			            "ODR0",
			            "ODR1",
			            "PCR",
			            "DSCR";                    /* in zephyr/dts/rx/renesas/rx130-common.dtsi:412 */
			pinmux = < &pinmuxa >;                 /* in zephyr/dts/rx/renesas/rx130-common.dtsi:413 */
			port-irqs = < &port_irq5 &port_irq6 >; /* in zephyr/dts/rx/renesas/rx130-common.dtsi:414 */
			port-irq-names = "port-irq5",
			                 "port-irq6";          /* in zephyr/dts/rx/renesas/rx130-common.dtsi:415 */
			port-irq5-pins = < 0x4 >;              /* in zephyr/dts/rx/renesas/rx130-common.dtsi:417 */
			port-irq6-pins = < 0x3 >;              /* in zephyr/dts/rx/renesas/rx130-common.dtsi:418 */
			status = "disabled";                   /* in zephyr/dts/rx/renesas/rx130-common.dtsi:419 */
		};

		/* node '/soc/gpio@8c00b' defined in zephyr/dts/rx/renesas/rx130-common.dtsi:422 */
		ioportb: gpio@8c00b {
			compatible = "renesas,rx-gpio"; /* in zephyr/dts/rx/renesas/rx130-common.dtsi:423 */
			gpio-controller;                /* in zephyr/dts/rx/renesas/rx130-common.dtsi:424 */
			#gpio-cells = < 0x2 >;          /* in zephyr/dts/rx/renesas/rx130-common.dtsi:425 */
			ngpios = < 0x8 >;               /* in zephyr/dts/rx/renesas/rx130-common.dtsi:426 */
			port = < 0xb >;                 /* in zephyr/dts/rx/renesas/rx130-common.dtsi:427 */
			reg = < 0x8c00b 0x1 >,
			      < 0x8c02b 0x1 >,
			      < 0x8c04b 0x1 >,
			      < 0x8c06b 0x1 >,
			      < 0x8c096 0x1 >,
			      < 0x8c097 0x1 >,
			      < 0x8c0cb 0x1 >,
			      < 0x8c0eb 0x1 >;          /* in zephyr/dts/rx/renesas/rx130-common.dtsi:428 */
			reg-names = "PDR",
			            "PODR",
			            "PIDR",
			            "PMR",
			            "ODR0",
			            "ODR1",
			            "PCR",
			            "DSCR";             /* in zephyr/dts/rx/renesas/rx130-common.dtsi:436 */
			pinmux = < &pinmuxb >;          /* in zephyr/dts/rx/renesas/rx130-common.dtsi:437 */
			port-irqs = < &port_irq4 >;     /* in zephyr/dts/rx/renesas/rx130-common.dtsi:438 */
			port-irq-names = "port-irq4";   /* in zephyr/dts/rx/renesas/rx130-common.dtsi:439 */
			port-irq4-pins = < 0x1 >;       /* in zephyr/dts/rx/renesas/rx130-common.dtsi:440 */
			status = "disabled";            /* in zephyr/dts/rx/renesas/rx130-common.dtsi:441 */
		};

		/* node '/soc/gpio@8c00c' defined in zephyr/dts/rx/renesas/rx130-common.dtsi:444 */
		ioportc: gpio@8c00c {
			compatible = "renesas,rx-gpio"; /* in zephyr/dts/rx/renesas/rx130-common.dtsi:445 */
			gpio-controller;                /* in zephyr/dts/rx/renesas/rx130-common.dtsi:446 */
			#gpio-cells = < 0x2 >;          /* in zephyr/dts/rx/renesas/rx130-common.dtsi:447 */
			ngpios = < 0x8 >;               /* in zephyr/dts/rx/renesas/rx130-common.dtsi:448 */
			port = < 0xc >;                 /* in zephyr/dts/rx/renesas/rx130-common.dtsi:449 */
			reg = < 0x8c00c 0x1 >,
			      < 0x8c02c 0x1 >,
			      < 0x8c04c 0x1 >,
			      < 0x8c06c 0x1 >,
			      < 0x8c098 0x1 >,
			      < 0x8c099 0x1 >,
			      < 0x8c0cc 0x1 >,
			      < 0x8c0ec 0x1 >;          /* in zephyr/dts/rx/renesas/rx130-common.dtsi:450 */
			reg-names = "PDR",
			            "PODR",
			            "PIDR",
			            "PMR",
			            "ODR0",
			            "ODR1",
			            "PCR",
			            "DSCR";             /* in zephyr/dts/rx/renesas/rx130-common.dtsi:458 */
			pinmux = < &pinmuxc >;          /* in zephyr/dts/rx/renesas/rx130-common.dtsi:459 */
			status = "okay";                /* in zephyr/boards/renesas/rsk_rx130/rsk_rx130.dts:90 */
			phandle = < 0x22 >;             /* in zephyr/boards/renesas/rsk_rx130/rsk_rx130.dts:129 */
		};

		/* node '/soc/gpio@8c00d' defined in zephyr/dts/rx/renesas/rx130-common.dtsi:463 */
		ioportd: gpio@8c00d {
			compatible = "renesas,rx-gpio";                                                                          /* in zephyr/dts/rx/renesas/rx130-common.dtsi:464 */
			gpio-controller;                                                                                         /* in zephyr/dts/rx/renesas/rx130-common.dtsi:465 */
			#gpio-cells = < 0x2 >;                                                                                   /* in zephyr/dts/rx/renesas/rx130-common.dtsi:466 */
			ngpios = < 0x8 >;                                                                                        /* in zephyr/dts/rx/renesas/rx130-common.dtsi:467 */
			port = < 0xd >;                                                                                          /* in zephyr/dts/rx/renesas/rx130-common.dtsi:468 */
			reg = < 0x8c00d 0x1 >,
			      < 0x8c02d 0x1 >,
			      < 0x8c04d 0x1 >,
			      < 0x8c06d 0x1 >,
			      < 0x8c09a 0x1 >,
			      < 0x8c0cd 0x1 >,
			      < 0x8c0ed 0x1 >;                                                                                   /* in zephyr/dts/rx/renesas/rx130-common.dtsi:469 */
			reg-names = "PDR",
			            "PODR",
			            "PIDR",
			            "PMR",
			            "ODR0",
			            "PCR",
			            "DSCR";                                                                                      /* in zephyr/dts/rx/renesas/rx130-common.dtsi:476 */
			pinmux = < &pinmuxd >;                                                                                   /* in zephyr/dts/rx/renesas/rx130-common.dtsi:477 */
			port-irqs = < &port_irq0 &port_irq1 &port_irq2 &port_irq3 &port_irq4 &port_irq5 &port_irq6 &port_irq7 >; /* in zephyr/dts/rx/renesas/rx130-common.dtsi:478 */
			port-irq-names = "port-irq0",
			                 "port-irq1",
			                 "port-irq2",
			                 "port-irq3",
			                 "port-irq4",
			                 "port-irq5",
			                 "port-irq6",
			                 "port-irq7";                                                                            /* in zephyr/dts/rx/renesas/rx130-common.dtsi:481 */
			port-irq0-pins = < 0x0 >;                                                                                /* in zephyr/dts/rx/renesas/rx130-common.dtsi:489 */
			port-irq1-pins = < 0x1 >;                                                                                /* in zephyr/dts/rx/renesas/rx130-common.dtsi:490 */
			port-irq2-pins = < 0x2 >;                                                                                /* in zephyr/dts/rx/renesas/rx130-common.dtsi:491 */
			port-irq3-pins = < 0x3 >;                                                                                /* in zephyr/dts/rx/renesas/rx130-common.dtsi:492 */
			port-irq4-pins = < 0x4 >;                                                                                /* in zephyr/dts/rx/renesas/rx130-common.dtsi:493 */
			port-irq5-pins = < 0x5 >;                                                                                /* in zephyr/dts/rx/renesas/rx130-common.dtsi:494 */
			port-irq6-pins = < 0x6 >;                                                                                /* in zephyr/dts/rx/renesas/rx130-common.dtsi:495 */
			port-irq7-pins = < 0x7 >;                                                                                /* in zephyr/dts/rx/renesas/rx130-common.dtsi:496 */
			status = "okay";                                                                                         /* in zephyr/boards/renesas/rsk_rx130/rsk_rx130.dts:94 */
			phandle = < 0x29 >;                                                                                      /* in zephyr/boards/renesas/rsk_rx130/rsk_rx130.dts:31 */
		};

		/* node '/soc/gpio@8c00e' defined in zephyr/dts/rx/renesas/rx130-common.dtsi:500 */
		ioporte: gpio@8c00e {
			compatible = "renesas,rx-gpio";                   /* in zephyr/dts/rx/renesas/rx130-common.dtsi:501 */
			gpio-controller;                                  /* in zephyr/dts/rx/renesas/rx130-common.dtsi:502 */
			#gpio-cells = < 0x2 >;                            /* in zephyr/dts/rx/renesas/rx130-common.dtsi:503 */
			ngpios = < 0x8 >;                                 /* in zephyr/dts/rx/renesas/rx130-common.dtsi:504 */
			port = < 0xe >;                                   /* in zephyr/dts/rx/renesas/rx130-common.dtsi:505 */
			reg = < 0x8c00e 0x1 >,
			      < 0x8c02e 0x1 >,
			      < 0x8c04e 0x1 >,
			      < 0x8c06e 0x1 >,
			      < 0x8c09c 0x1 >,
			      < 0x8c0ce 0x1 >,
			      < 0x8c0ee 0x1 >;                            /* in zephyr/dts/rx/renesas/rx130-common.dtsi:506 */
			reg-names = "PDR",
			            "PODR",
			            "PIDR",
			            "PMR",
			            "ODR0",
			            "PCR",
			            "DSCR";                               /* in zephyr/dts/rx/renesas/rx130-common.dtsi:513 */
			pinmux = < &pinmuxe >;                            /* in zephyr/dts/rx/renesas/rx130-common.dtsi:514 */
			port-irqs = < &port_irq5 &port_irq6 &port_irq7 >; /* in zephyr/dts/rx/renesas/rx130-common.dtsi:515 */
			port-irq-names = "port-irq5",
			                 "port-irq6",
			                 "port-irq7";                     /* in zephyr/dts/rx/renesas/rx130-common.dtsi:516 */
			port-irq5-pins = < 0x5 >;                         /* in zephyr/dts/rx/renesas/rx130-common.dtsi:519 */
			port-irq6-pins = < 0x6 >;                         /* in zephyr/dts/rx/renesas/rx130-common.dtsi:520 */
			port-irq7-pins = < 0x2 0x7 >;                     /* in zephyr/dts/rx/renesas/rx130-common.dtsi:521 */
			status = "okay";                                  /* in zephyr/boards/renesas/rsk_rx130/rsk_rx130.dts:98 */
			phandle = < 0x2a >;                               /* in zephyr/boards/renesas/rsk_rx130/rsk_rx130.dts:36 */
		};

		/* node '/soc/gpio@8c011' defined in zephyr/dts/rx/renesas/rx130-common.dtsi:525 */
		ioporth: gpio@8c011 {
			compatible = "renesas,rx-gpio";        /* in zephyr/dts/rx/renesas/rx130-common.dtsi:526 */
			gpio-controller;                       /* in zephyr/dts/rx/renesas/rx130-common.dtsi:527 */
			#gpio-cells = < 0x2 >;                 /* in zephyr/dts/rx/renesas/rx130-common.dtsi:528 */
			ngpios = < 0x8 >;                      /* in zephyr/dts/rx/renesas/rx130-common.dtsi:529 */
			port = < 0x11 >;                       /* in zephyr/dts/rx/renesas/rx130-common.dtsi:530 */
			reg = < 0x8c011 0x1 >,
			      < 0x8c031 0x1 >,
			      < 0x8c051 0x1 >,
			      < 0x8c071 0x1 >,
			      < 0x8c0d1 0x1 >,
			      < 0x8c0f1 0x1 >;                 /* in zephyr/dts/rx/renesas/rx130-common.dtsi:531 */
			reg-names = "PDR",
			            "PODR",
			            "PIDR",
			            "PMR",
			            "PCR",
			            "DSCR";                    /* in zephyr/dts/rx/renesas/rx130-common.dtsi:537 */
			pinmux = < &pinmuxh >;                 /* in zephyr/dts/rx/renesas/rx130-common.dtsi:538 */
			port-irqs = < &port_irq0 &port_irq1 >; /* in zephyr/dts/rx/renesas/rx130-common.dtsi:539 */
			port-irq-names = "port-irq0",
			                 "port-irq1";          /* in zephyr/dts/rx/renesas/rx130-common.dtsi:540 */
			port-irq0-pins = < 0x1 >;              /* in zephyr/dts/rx/renesas/rx130-common.dtsi:542 */
			port-irq1-pins = < 0x2 >;              /* in zephyr/dts/rx/renesas/rx130-common.dtsi:543 */
			status = "disabled";                   /* in zephyr/dts/rx/renesas/rx130-common.dtsi:544 */
		};

		/* node '/soc/gpio@8c012' defined in zephyr/dts/rx/renesas/rx130-common.dtsi:547 */
		ioportj: gpio@8c012 {
			compatible = "renesas,rx-gpio"; /* in zephyr/dts/rx/renesas/rx130-common.dtsi:548 */
			gpio-controller;                /* in zephyr/dts/rx/renesas/rx130-common.dtsi:549 */
			#gpio-cells = < 0x2 >;          /* in zephyr/dts/rx/renesas/rx130-common.dtsi:550 */
			ngpios = < 0x8 >;               /* in zephyr/dts/rx/renesas/rx130-common.dtsi:551 */
			port = < 0x12 >;                /* in zephyr/dts/rx/renesas/rx130-common.dtsi:552 */
			reg = < 0x8c012 0x1 >,
			      < 0x8c032 0x1 >,
			      < 0x8c052 0x1 >,
			      < 0x8c072 0x1 >,
			      < 0x8c0a4 0x1 >,
			      < 0x8c0d2 0x1 >,
			      < 0x8c0f2 0x1 >;          /* in zephyr/dts/rx/renesas/rx130-common.dtsi:553 */
			reg-names = "PDR",
			            "PODR",
			            "PIDR",
			            "PMR",
			            "ODR0",
			            "PCR",
			            "DSCR";             /* in zephyr/dts/rx/renesas/rx130-common.dtsi:560 */
			pinmux = < &pinmuxj >;          /* in zephyr/dts/rx/renesas/rx130-common.dtsi:561 */
			status = "disabled";            /* in zephyr/dts/rx/renesas/rx130-common.dtsi:562 */
		};

		/* node '/soc/sci0@8a000' defined in zephyr/dts/rx/renesas/rx130-common.dtsi:565 */
		sci0: sci0@8a000 {
			compatible = "renesas,rx-sci"; /* in zephyr/dts/rx/renesas/rx130-common.dtsi:566 */
			interrupts = < 0xd7 0x1 >,
			             < 0xd8 0x1 >,
			             < 0xd9 0x1 >,
			             < 0xd6 0x1 >;     /* in zephyr/dts/rx/renesas/rx130-common.dtsi:567 */
			interrupt-names = "rxi",
			                  "txi",
			                  "tei",
			                  "eri";       /* in zephyr/dts/rx/renesas/rx130-common.dtsi:568 */
			reg = < 0x8a000 0x20 >;        /* in zephyr/dts/rx/renesas/rx130-common.dtsi:569 */
			clocks = < &pclkb 0x1 0x1f >;  /* in zephyr/dts/rx/renesas/rx130-common.dtsi:570 */
			channel = < 0x0 >;             /* in zephyr/dts/rx/renesas/rx130-common.dtsi:571 */
			dtc = < &dtc >;                /* in zephyr/dts/rx/renesas/rx130-common.dtsi:572 */
			status = "disabled";           /* in zephyr/dts/rx/renesas/rx130-common.dtsi:573 */

			/* node '/soc/sci0@8a000/uart' defined in zephyr/dts/rx/renesas/rx130-common.dtsi:575 */
			uart {
				compatible = "renesas,rx-uart-sci"; /* in zephyr/dts/rx/renesas/rx130-common.dtsi:576 */
				status = "disabled";                /* in zephyr/dts/rx/renesas/rx130-common.dtsi:577 */
			};
		};

		/* node '/soc/sci1@8a020' defined in zephyr/dts/rx/renesas/rx130-common.dtsi:581 */
		sci1: sci1@8a020 {
			compatible = "renesas,rx-sci"; /* in zephyr/dts/rx/renesas/rx130-common.dtsi:582 */
			interrupts = < 0xdb 0x1 >,
			             < 0xdc 0x1 >,
			             < 0xdd 0x1 >,
			             < 0xda 0x1 >;     /* in zephyr/dts/rx/renesas/rx130-common.dtsi:583 */
			interrupt-names = "rxi",
			                  "txi",
			                  "tei",
			                  "eri";       /* in zephyr/dts/rx/renesas/rx130-common.dtsi:584 */
			reg = < 0x8a020 0x20 >;        /* in zephyr/dts/rx/renesas/rx130-common.dtsi:585 */
			clocks = < &pclkb 0x1 0x1e >;  /* in zephyr/dts/rx/renesas/rx130-common.dtsi:586 */
			channel = < 0x1 >;             /* in zephyr/dts/rx/renesas/rx130-common.dtsi:587 */
			dtc = < &dtc >;                /* in zephyr/dts/rx/renesas/rx130-common.dtsi:588 */
			pinctrl-0 = < &sci1_default >; /* in zephyr/boards/renesas/rsk_rx130/rsk_rx130.dts:102 */
			pinctrl-names = "default";     /* in zephyr/boards/renesas/rsk_rx130/rsk_rx130.dts:103 */
			status = "okay";               /* in zephyr/boards/renesas/rsk_rx130/rsk_rx130.dts:104 */

			/* node '/soc/sci1@8a020/uart' defined in zephyr/dts/rx/renesas/rx130-common.dtsi:591 */
			uart1: uart {
				compatible = "renesas,rx-uart-sci"; /* in zephyr/dts/rx/renesas/rx130-common.dtsi:592 */
				current-speed = < 0x1c200 >;        /* in zephyr/boards/renesas/rsk_rx130/rsk_rx130.dts:107 */
				status = "okay";                    /* in zephyr/boards/renesas/rsk_rx130/rsk_rx130.dts:108 */
			};
		};

		/* node '/soc/sci5@8a0a0' defined in zephyr/dts/rx/renesas/rx130-common.dtsi:597 */
		sci5: sci5@8a0a0 {
			compatible = "renesas,rx-sci"; /* in zephyr/dts/rx/renesas/rx130-common.dtsi:598 */
			interrupts = < 0xdf 0x1 >,
			             < 0xe0 0x1 >,
			             < 0xe1 0x1 >,
			             < 0xde 0x1 >;     /* in zephyr/dts/rx/renesas/rx130-common.dtsi:599 */
			interrupt-names = "rxi",
			                  "txi",
			                  "tei",
			                  "eri";       /* in zephyr/dts/rx/renesas/rx130-common.dtsi:600 */
			reg = < 0x8a0a0 0x20 >;        /* in zephyr/dts/rx/renesas/rx130-common.dtsi:601 */
			clocks = < &pclkb 0x1 0x1a >;  /* in zephyr/dts/rx/renesas/rx130-common.dtsi:602 */
			channel = < 0x5 >;             /* in zephyr/dts/rx/renesas/rx130-common.dtsi:603 */
			dtc = < &dtc >;                /* in zephyr/dts/rx/renesas/rx130-common.dtsi:604 */
			status = "disabled";           /* in zephyr/dts/rx/renesas/rx130-common.dtsi:605 */

			/* node '/soc/sci5@8a0a0/uart' defined in zephyr/dts/rx/renesas/rx130-common.dtsi:607 */
			uart {
				compatible = "renesas,rx-uart-sci"; /* in zephyr/dts/rx/renesas/rx130-common.dtsi:608 */
				status = "disabled";                /* in zephyr/dts/rx/renesas/rx130-common.dtsi:609 */
			};
		};

		/* node '/soc/sci6@8a0c0' defined in zephyr/dts/rx/renesas/rx130-common.dtsi:613 */
		sci6: sci6@8a0c0 {
			compatible = "renesas,rx-sci"; /* in zephyr/dts/rx/renesas/rx130-common.dtsi:614 */
			interrupts = < 0xe3 0x1 >,
			             < 0xe4 0x1 >,
			             < 0xe5 0x1 >,
			             < 0xe2 0x1 >;     /* in zephyr/dts/rx/renesas/rx130-common.dtsi:615 */
			interrupt-names = "rxi",
			                  "txi",
			                  "tei",
			                  "eri";       /* in zephyr/dts/rx/renesas/rx130-common.dtsi:616 */
			reg = < 0x8a0c0 0x20 >;        /* in zephyr/dts/rx/renesas/rx130-common.dtsi:617 */
			clocks = < &pclkb 0x1 0x19 >;  /* in zephyr/dts/rx/renesas/rx130-common.dtsi:618 */
			channel = < 0x6 >;             /* in zephyr/dts/rx/renesas/rx130-common.dtsi:619 */
			dtc = < &dtc >;                /* in zephyr/dts/rx/renesas/rx130-common.dtsi:620 */
			status = "disabled";           /* in zephyr/dts/rx/renesas/rx130-common.dtsi:621 */

			/* node '/soc/sci6@8a0c0/uart' defined in zephyr/dts/rx/renesas/rx130-common.dtsi:623 */
			uart {
				compatible = "renesas,rx-uart-sci"; /* in zephyr/dts/rx/renesas/rx130-common.dtsi:624 */
				status = "disabled";                /* in zephyr/dts/rx/renesas/rx130-common.dtsi:625 */
			};
		};

		/* node '/soc/sci8@8a100' defined in zephyr/dts/rx/renesas/rx130-common.dtsi:629 */
		sci8: sci8@8a100 {
			compatible = "renesas,rx-sci"; /* in zephyr/dts/rx/renesas/rx130-common.dtsi:630 */
			interrupts = < 0xe7 0x1 >,
			             < 0xe8 0x1 >,
			             < 0xe9 0x1 >,
			             < 0xe6 0x1 >;     /* in zephyr/dts/rx/renesas/rx130-common.dtsi:631 */
			interrupt-names = "rxi",
			                  "txi",
			                  "tei",
			                  "eri";       /* in zephyr/dts/rx/renesas/rx130-common.dtsi:632 */
			reg = < 0x8a100 0x20 >;        /* in zephyr/dts/rx/renesas/rx130-common.dtsi:633 */
			clocks = < &pclkb 0x2 0x1b >;  /* in zephyr/dts/rx/renesas/rx130-common.dtsi:634 */
			channel = < 0x8 >;             /* in zephyr/dts/rx/renesas/rx130-common.dtsi:635 */
			dtc = < &dtc >;                /* in zephyr/dts/rx/renesas/rx130-common.dtsi:636 */
			status = "disabled";           /* in zephyr/dts/rx/renesas/rx130-common.dtsi:637 */

			/* node '/soc/sci8@8a100/uart' defined in zephyr/dts/rx/renesas/rx130-common.dtsi:639 */
			uart {
				compatible = "renesas,rx-uart-sci"; /* in zephyr/dts/rx/renesas/rx130-common.dtsi:640 */
				status = "disabled";                /* in zephyr/dts/rx/renesas/rx130-common.dtsi:641 */
			};
		};

		/* node '/soc/mtu@88680' defined in zephyr/dts/rx/renesas/rx130-common.dtsi:645 */
		mtu2a: mtu@88680 {
			compatible = "renesas,rx-mtu2a"; /* in zephyr/dts/rx/renesas/rx130-common.dtsi:647 */
			#address-cells = < 0x1 >;        /* in zephyr/dts/rx/renesas/rx130-common.dtsi:648 */
			#size-cells = < 0x1 >;           /* in zephyr/dts/rx/renesas/rx130-common.dtsi:649 */
			reg = < 0x88680 0x1 >,
			      < 0x88681 0x1 >;           /* in zephyr/dts/rx/renesas/rx130-common.dtsi:650 */
			reg-names = "TSTR",
			            "TSYR";              /* in zephyr/dts/rx/renesas/rx130-common.dtsi:651 */

			/* node '/soc/mtu@88680/mtu0@88700' defined in zephyr/dts/rx/renesas/rx130-common.dtsi:653 */
			mtu0: mtu0@88700 {
				compatible = "renesas,rx-mtu"; /* in zephyr/dts/rx/renesas/rx130-common.dtsi:654 */
				channel = < 0x0 >;             /* in zephyr/dts/rx/renesas/rx130-common.dtsi:655 */
				interrupts = < 0x72 0x1 >,
				             < 0x73 0x1 >,
				             < 0x74 0x1 >,
				             < 0x75 0x3 >,
				             < 0x76 0x4 >;     /* in zephyr/dts/rx/renesas/rx130-common.dtsi:656 */
				interrupt-names = "tgia",
				                  "tgib",
				                  "tgic",
				                  "tgid",
				                  "tgiv";      /* in zephyr/dts/rx/renesas/rx130-common.dtsi:657 */
				clocks = < &pclkb 0x0 0x9 >;   /* in zephyr/dts/rx/renesas/rx130-common.dtsi:658 */
				reg-names = "TCR",
				            "TMDR",
				            "TIOR",
				            "TIER",
				            "TSR",
				            "TGR",
				            "TCNT",
				            "NFCR";            /* in zephyr/dts/rx/renesas/rx130-common.dtsi:659 */
				reg = < 0x88700 0x1 >,
				      < 0x88701 0x1 >,
				      < 0x88702 0x2 >,
				      < 0x88704 0x1 >,
				      < 0x88705 0x1 >,
				      < 0x88708 0x8 >,
				      < 0x88706 0x2 >,
				      < 0x88690 0x1 >;         /* in zephyr/dts/rx/renesas/rx130-common.dtsi:661 */
				bit-idx = < 0x0 >;             /* in zephyr/dts/rx/renesas/rx130-common.dtsi:669 */

				/* node '/soc/mtu@88680/mtu0@88700/pwm' defined in zephyr/dts/rx/renesas/rx130-common.dtsi:671 */
				pwm {
					compatible = "renesas,rx-mtu-pwm"; /* in zephyr/dts/rx/renesas/rx130-common.dtsi:672 */
					prescaler = < 0x2 >;               /* in zephyr/dts/rx/renesas/rx130-common.dtsi:673 */
					#pwm-cells = < 0x3 >;              /* in zephyr/dts/rx/renesas/rx130-common.dtsi:674 */
					status = "disabled";               /* in zephyr/dts/rx/renesas/rx130-common.dtsi:675 */
				};
			};

			/* node '/soc/mtu@88680/mtu1@88780' defined in zephyr/dts/rx/renesas/rx130-common.dtsi:679 */
			mtu1: mtu1@88780 {
				compatible = "renesas,rx-mtu"; /* in zephyr/dts/rx/renesas/rx130-common.dtsi:680 */
				channel = < 0x1 >;             /* in zephyr/dts/rx/renesas/rx130-common.dtsi:681 */
				interrupts = < 0x79 0x1 >,
				             < 0x7a 0x1 >,
				             < 0x7b 0x1 >;     /* in zephyr/dts/rx/renesas/rx130-common.dtsi:682 */
				interrupt-names = "tgia",
				                  "tgib",
				                  "tgiv";      /* in zephyr/dts/rx/renesas/rx130-common.dtsi:683 */
				clocks = < &pclkb 0x0 0x9 >;   /* in zephyr/dts/rx/renesas/rx130-common.dtsi:684 */
				reg = < 0x88780 0x1 >,
				      < 0x88781 0x1 >,
				      < 0x88782 0x1 >,
				      < 0x88784 0x1 >,
				      < 0x88785 0x1 >,
				      < 0x88788 0x4 >,
				      < 0x88786 0x2 >,
				      < 0x88691 0x1 >;         /* in zephyr/dts/rx/renesas/rx130-common.dtsi:685 */
				reg-names = "TCR",
				            "TMDR",
				            "TIOR",
				            "TIER",
				            "TSR",
				            "TGR",
				            "TCNT",
				            "NFCR";            /* in zephyr/dts/rx/renesas/rx130-common.dtsi:693 */
				bit-idx = < 0x1 >;             /* in zephyr/dts/rx/renesas/rx130-common.dtsi:695 */
				status = "okay";               /* in zephyr/boards/renesas/rsk_rx130/rsk_rx130.dts:182 */
				pinctrl-0 = < &pwm1_default >; /* in zephyr/boards/renesas/rsk_rx130/rsk_rx130.dts:183 */
				pinctrl-names = "default";     /* in zephyr/boards/renesas/rsk_rx130/rsk_rx130.dts:184 */

				/* node '/soc/mtu@88680/mtu1@88780/pwm' defined in zephyr/dts/rx/renesas/rx130-common.dtsi:697 */
				pwm1: pwm {
					compatible = "renesas,rx-mtu-pwm"; /* in zephyr/dts/rx/renesas/rx130-common.dtsi:698 */
					prescaler = < 0x2 >;               /* in zephyr/dts/rx/renesas/rx130-common.dtsi:699 */
					#pwm-cells = < 0x3 >;              /* in zephyr/dts/rx/renesas/rx130-common.dtsi:700 */
					status = "okay";                   /* in zephyr/boards/renesas/rsk_rx130/rsk_rx130.dts:187 */
				};
			};

			/* node '/soc/mtu@88680/mtu2@88800' defined in zephyr/dts/rx/renesas/rx130-common.dtsi:705 */
			mtu2: mtu2@88800 {
				compatible = "renesas,rx-mtu"; /* in zephyr/dts/rx/renesas/rx130-common.dtsi:706 */
				channel = < 0x2 >;             /* in zephyr/dts/rx/renesas/rx130-common.dtsi:707 */
				interrupts = < 0x7d 0x1 >,
				             < 0x7e 0x1 >,
				             < 0x7f 0x1 >;     /* in zephyr/dts/rx/renesas/rx130-common.dtsi:708 */
				interrupt-names = "tgia",
				                  "tgib",
				                  "tgiv";      /* in zephyr/dts/rx/renesas/rx130-common.dtsi:709 */
				clocks = < &pclkb 0x0 0x9 >;   /* in zephyr/dts/rx/renesas/rx130-common.dtsi:710 */
				reg = < 0x88800 0x1 >,
				      < 0x88801 0x1 >,
				      < 0x88802 0x1 >,
				      < 0x88804 0x1 >,
				      < 0x88805 0x1 >,
				      < 0x88808 0x4 >,
				      < 0x88806 0x2 >,
				      < 0x88692 0x1 >;         /* in zephyr/dts/rx/renesas/rx130-common.dtsi:711 */
				reg-names = "TCR",
				            "TMDR",
				            "TIOR",
				            "TIER",
				            "TSR",
				            "TGR",
				            "TCNT",
				            "NFCR";            /* in zephyr/dts/rx/renesas/rx130-common.dtsi:719 */
				bit-idx = < 0x2 >;             /* in zephyr/dts/rx/renesas/rx130-common.dtsi:721 */

				/* node '/soc/mtu@88680/mtu2@88800/pwm' defined in zephyr/dts/rx/renesas/rx130-common.dtsi:723 */
				pwm {
					compatible = "renesas,rx-mtu-pwm"; /* in zephyr/dts/rx/renesas/rx130-common.dtsi:724 */
					prescaler = < 0x0 >;               /* in zephyr/dts/rx/renesas/rx130-common.dtsi:725 */
					#pwm-cells = < 0x3 >;              /* in zephyr/dts/rx/renesas/rx130-common.dtsi:726 */
					status = "disabled";               /* in zephyr/dts/rx/renesas/rx130-common.dtsi:727 */
				};
			};

			/* node '/soc/mtu@88680/mtu3@88600' defined in zephyr/dts/rx/renesas/rx130-common.dtsi:731 */
			mtu3: mtu3@88600 {
				compatible = "renesas,rx-mtu"; /* in zephyr/dts/rx/renesas/rx130-common.dtsi:732 */
				channel = < 0x3 >;             /* in zephyr/dts/rx/renesas/rx130-common.dtsi:733 */
				interrupts = < 0x81 0x1 >,
				             < 0x82 0x1 >,
				             < 0x83 0x1 >,
				             < 0x84 0x1 >,
				             < 0x85 0x1 >;     /* in zephyr/dts/rx/renesas/rx130-common.dtsi:734 */
				interrupt-names = "tgia",
				                  "tgib",
				                  "tgic",
				                  "tgid",
				                  "tgiv";      /* in zephyr/dts/rx/renesas/rx130-common.dtsi:735 */
				clocks = < &pclkb 0x0 0x9 >;   /* in zephyr/dts/rx/renesas/rx130-common.dtsi:736 */
				reg = < 0x88600 0x1 >,
				      < 0x88602 0x1 >,
				      < 0x88604 0x2 >,
				      < 0x88608 0x1 >,
				      < 0x8862c 0x1 >,
				      < 0x88618 0x8 >,
				      < 0x88610 0x2 >,
				      < 0x88693 0x1 >;         /* in zephyr/dts/rx/renesas/rx130-common.dtsi:737 */
				reg-names = "TCR",
				            "TMDR",
				            "TIOR",
				            "TIER",
				            "TSR",
				            "TGR",
				            "TCNT",
				            "NFCR";            /* in zephyr/dts/rx/renesas/rx130-common.dtsi:745 */
				bit-idx = < 0x6 >;             /* in zephyr/dts/rx/renesas/rx130-common.dtsi:747 */

				/* node '/soc/mtu@88680/mtu3@88600/pwm' defined in zephyr/dts/rx/renesas/rx130-common.dtsi:749 */
				pwm {
					compatible = "renesas,rx-mtu-pwm"; /* in zephyr/dts/rx/renesas/rx130-common.dtsi:750 */
					prescaler = < 0x0 >;               /* in zephyr/dts/rx/renesas/rx130-common.dtsi:751 */
					#pwm-cells = < 0x3 >;              /* in zephyr/dts/rx/renesas/rx130-common.dtsi:752 */
					status = "disabled";               /* in zephyr/dts/rx/renesas/rx130-common.dtsi:753 */
				};
			};

			/* node '/soc/mtu@88680/mtu4@88601' defined in zephyr/dts/rx/renesas/rx130-common.dtsi:757 */
			mtu4: mtu4@88601 {
				compatible = "renesas,rx-mtu"; /* in zephyr/dts/rx/renesas/rx130-common.dtsi:758 */
				channel = < 0x4 >;             /* in zephyr/dts/rx/renesas/rx130-common.dtsi:759 */
				interrupts = < 0x86 0x1 >,
				             < 0x87 0x1 >,
				             < 0x88 0x1 >,
				             < 0x89 0x1 >,
				             < 0x8a 0x1 >;     /* in zephyr/dts/rx/renesas/rx130-common.dtsi:760 */
				interrupt-names = "tgia",
				                  "tgib",
				                  "tgic",
				                  "tgid",
				                  "tgiv";      /* in zephyr/dts/rx/renesas/rx130-common.dtsi:761 */
				clocks = < &pclkb 0x0 0x9 >;   /* in zephyr/dts/rx/renesas/rx130-common.dtsi:762 */
				reg = < 0x88601 0x1 >,
				      < 0x88603 0x1 >,
				      < 0x88606 0x2 >,
				      < 0x88609 0x1 >,
				      < 0x8862c 0x1 >,
				      < 0x8861c 0x8 >,
				      < 0x88612 0x2 >,
				      < 0x88694 0x1 >;         /* in zephyr/dts/rx/renesas/rx130-common.dtsi:763 */
				reg-names = "TCR",
				            "TMDR",
				            "TIOR",
				            "TIER",
				            "TSR",
				            "TGR",
				            "TCNT",
				            "NFCR";            /* in zephyr/dts/rx/renesas/rx130-common.dtsi:771 */
				bit-idx = < 0x7 >;             /* in zephyr/dts/rx/renesas/rx130-common.dtsi:773 */

				/* node '/soc/mtu@88680/mtu4@88601/pwm' defined in zephyr/dts/rx/renesas/rx130-common.dtsi:775 */
				pwm {
					compatible = "renesas,rx-mtu-pwm"; /* in zephyr/dts/rx/renesas/rx130-common.dtsi:776 */
					prescaler = < 0x0 >;               /* in zephyr/dts/rx/renesas/rx130-common.dtsi:777 */
					#pwm-cells = < 0x3 >;              /* in zephyr/dts/rx/renesas/rx130-common.dtsi:778 */
					status = "disabled";               /* in zephyr/dts/rx/renesas/rx130-common.dtsi:779 */
				};
			};
		};

		/* node '/soc/sci9@8a120' defined in zephyr/dts/rx/renesas/rx130-common.dtsi:784 */
		sci9: sci9@8a120 {
			compatible = "renesas,rx-sci"; /* in zephyr/dts/rx/renesas/rx130-common.dtsi:785 */
			interrupts = < 0xeb 0x1 >,
			             < 0xec 0x1 >,
			             < 0xed 0x1 >,
			             < 0xea 0x1 >;     /* in zephyr/dts/rx/renesas/rx130-common.dtsi:786 */
			interrupt-names = "rxi",
			                  "txi",
			                  "tei",
			                  "eri";       /* in zephyr/dts/rx/renesas/rx130-common.dtsi:787 */
			reg = < 0x8a120 0x20 >;        /* in zephyr/dts/rx/renesas/rx130-common.dtsi:788 */
			clocks = < &pclkb 0x2 0x1a >;  /* in zephyr/dts/rx/renesas/rx130-common.dtsi:789 */
			status = "disabled";           /* in zephyr/dts/rx/renesas/rx130-common.dtsi:790 */
			channel = < 0x9 >;             /* in zephyr/dts/rx/renesas/rx130-common.dtsi:791 */

			/* node '/soc/sci9@8a120/uart' defined in zephyr/dts/rx/renesas/rx130-common.dtsi:793 */
			uart {
				compatible = "renesas,rx-uart-sci"; /* in zephyr/dts/rx/renesas/rx130-common.dtsi:794 */
				status = "disabled";                /* in zephyr/dts/rx/renesas/rx130-common.dtsi:795 */
			};
		};

		/* node '/soc/i2c@88300' defined in zephyr/dts/rx/renesas/rx130-common.dtsi:799 */
		i2c0: i2c@88300 {
			compatible = "renesas,rx-i2c"; /* in zephyr/dts/rx/renesas/rx130-common.dtsi:800 */
			#address-cells = < 0x1 >;      /* in zephyr/dts/rx/renesas/rx130-common.dtsi:801 */
			#size-cells = < 0x0 >;         /* in zephyr/dts/rx/renesas/rx130-common.dtsi:802 */
			reg = < 0x88300 0x20 >;        /* in zephyr/dts/rx/renesas/rx130-common.dtsi:803 */
			channel = < 0x0 >;             /* in zephyr/dts/rx/renesas/rx130-common.dtsi:804 */
			interrupts = < 0xf6 0x1 >,
			             < 0xf7 0x1 >,
			             < 0xf8 0x1 >,
			             < 0xf9 0x1 >;     /* in zephyr/dts/rx/renesas/rx130-common.dtsi:805 */
			interrupt-names = "eei",
			                  "rxi",
			                  "txi",
			                  "tei";       /* in zephyr/dts/rx/renesas/rx130-common.dtsi:806 */
			status = "disabled";           /* in zephyr/dts/rx/renesas/rx130-common.dtsi:807 */
			pinctrl-0 = < &i2c0_default >; /* in zephyr/boards/renesas/rsk_rx130/rsk_rx130.dts:120 */
			pinctrl-names = "default";     /* in zephyr/boards/renesas/rsk_rx130/rsk_rx130.dts:121 */
			clock-frequency = < 0x61a80 >; /* in zephyr/boards/renesas/rsk_rx130/rsk_rx130.dts:122 */
		};

		/* node '/soc/timer@88000' defined in zephyr/dts/rx/renesas/rx130-common.dtsi:810 */
		cmt: timer@88000 {
			compatible = "renesas,rx-timer-cmt-start-control"; /* in zephyr/dts/rx/renesas/rx130-common.dtsi:811 */
			#address-cells = < 0x1 >;                          /* in zephyr/dts/rx/renesas/rx130-common.dtsi:812 */
			#size-cells = < 0x1 >;                             /* in zephyr/dts/rx/renesas/rx130-common.dtsi:813 */
			reg = < 0x88000 0x2 >;                             /* in zephyr/dts/rx/renesas/rx130-common.dtsi:814 */
			clocks = < &pclkb 0x0 0xf >;                       /* in zephyr/dts/rx/renesas/rx130-common.dtsi:815 */
			reg-names = "CMSTR0";                              /* in zephyr/dts/rx/renesas/rx130-common.dtsi:816 */
			clock-frequency = < 0x3d0900 >;                    /* in zephyr/boards/renesas/rsk_rx130/rsk_rx130.dts:81 */
			status = "okay";                                   /* in zephyr/boards/renesas/rsk_rx130/rsk_rx130.dts:82 */

			/* node '/soc/timer@88000/timer@88002' defined in zephyr/dts/rx/renesas/rx130-common.dtsi:819 */
			cmt0: timer@88002 {
				compatible = "renesas,rx-timer-cmt"; /* in zephyr/dts/rx/renesas/rx130-common.dtsi:820 */
				#address-cells = < 0x1 >;            /* in zephyr/dts/rx/renesas/rx130-common.dtsi:821 */
				#size-cells = < 0x1 >;               /* in zephyr/dts/rx/renesas/rx130-common.dtsi:822 */
				reg = < 0x88002 0x2 >,
				      < 0x88004 0x2 >,
				      < 0x88006 0x2 >;               /* in zephyr/dts/rx/renesas/rx130-common.dtsi:823 */
				reg-names = "CMCR",
				            "CMCNT",
				            "CMCOR";                 /* in zephyr/dts/rx/renesas/rx130-common.dtsi:826 */
				interrupts = < 0x1c 0x1 >;           /* in zephyr/dts/rx/renesas/rx130-common.dtsi:827 */
				interrupt-names = "cmi";             /* in zephyr/dts/rx/renesas/rx130-common.dtsi:828 */
				status = "okay";                     /* in zephyr/dts/rx/renesas/rx130-common.dtsi:829 */
			};

			/* node '/soc/timer@88000/timer@88008' defined in zephyr/dts/rx/renesas/rx130-common.dtsi:832 */
			cmt1: timer@88008 {
				compatible = "renesas,rx-timer-cmt"; /* in zephyr/dts/rx/renesas/rx130-common.dtsi:833 */
				reg = < 0x88008 0x2 >,
				      < 0x8800a 0x2 >,
				      < 0x8800c 0x2 >;               /* in zephyr/dts/rx/renesas/rx130-common.dtsi:834 */
				reg-names = "CMCR",
				            "CMCNT",
				            "CMCOR";                 /* in zephyr/dts/rx/renesas/rx130-common.dtsi:837 */
				interrupts = < 0x1d 0x1 >;           /* in zephyr/dts/rx/renesas/rx130-common.dtsi:838 */
				interrupt-names = "cmi";             /* in zephyr/dts/rx/renesas/rx130-common.dtsi:839 */
				status = "disabled";                 /* in zephyr/dts/rx/renesas/rx130-common.dtsi:840 */
			};
		};

		/* node '/soc/spi@88380' defined in zephyr/dts/rx/renesas/rx130-common.dtsi:844 */
		rspi0: spi@88380 {
			compatible = "renesas,rx-rspi"; /* in zephyr/dts/rx/renesas/rx130-common.dtsi:845 */
			#address-cells = < 0x1 >;       /* in zephyr/dts/rx/renesas/rx130-common.dtsi:846 */
			#size-cells = < 0x0 >;          /* in zephyr/dts/rx/renesas/rx130-common.dtsi:847 */
			reg = < 0x88380 0x100 >;        /* in zephyr/dts/rx/renesas/rx130-common.dtsi:848 */
			channel = < 0x0 >;              /* in zephyr/dts/rx/renesas/rx130-common.dtsi:849 */
			clocks = < &pclkb 0x1 0x11 >;   /* in zephyr/dts/rx/renesas/rx130-common.dtsi:850 */
			interrupts = < 0x2c 0x1 >,
			             < 0x2d 0x1 >,
			             < 0x2e 0x1 >,
			             < 0x2f 0x1 >;      /* in zephyr/dts/rx/renesas/rx130-common.dtsi:851 */
			interrupt-names = "spei",
			                  "spri",
			                  "spti",
			                  "spii";       /* in zephyr/dts/rx/renesas/rx130-common.dtsi:852 */
			pinctrl-0 = < &rspi0_default >; /* in zephyr/boards/renesas/rsk_rx130/rsk_rx130.dts:113 */
			pinctrl-names = "default";      /* in zephyr/boards/renesas/rsk_rx130/rsk_rx130.dts:114 */
			ssl-assert = < 0x0 >;           /* in zephyr/boards/renesas/rsk_rx130/rsk_rx130.dts:115 */
			status = "okay";                /* in zephyr/boards/renesas/rsk_rx130/rsk_rx130.dts:116 */
		};

		/* node '/soc/adc@89000' defined in zephyr/dts/rx/renesas/rx130-common.dtsi:856 */
		adc: adc@89000 {
			compatible = "renesas,rx-adc";           /* in zephyr/dts/rx/renesas/rx130-common.dtsi:857 */
			interrupts = < 0x66 0x1 >;               /* in zephyr/dts/rx/renesas/rx130-common.dtsi:858 */
			interrupt-names = "s12adi0";             /* in zephyr/dts/rx/renesas/rx130-common.dtsi:859 */
			reg = < 0x89000 0x100 >;                 /* in zephyr/dts/rx/renesas/rx130-common.dtsi:860 */
			#io-channel-cells = < 0x1 >;             /* in zephyr/dts/rx/renesas/rx130-common.dtsi:861 */
			channel-available-mask = < 0xffff00ff >; /* in zephyr/dts/rx/renesas/rx130-common.dtsi:862 */
			vref-mv = < 0xce4 >;                     /* in zephyr/dts/rx/renesas/rx130-common.dtsi:863 */
			channel-count = < 0x18 >;                /* in zephyr/dts/rx/renesas/rx130-common.dtsi:864 */
			pinctrl-0 = < &adc_default >;            /* in zephyr/boards/renesas/rsk_rx130/rsk_rx130.dts:205 */
			pinctrl-names = "default";               /* in zephyr/boards/renesas/rsk_rx130/rsk_rx130.dts:206 */
			status = "okay";                         /* in zephyr/boards/renesas/rsk_rx130/rsk_rx130.dts:207 */
		};

		/* node '/soc/ctsu@a0900' defined in zephyr/dts/rx/renesas/rx130-common.dtsi:868 */
		ctsu: ctsu@a0900 {
			compatible = "renesas,rx-ctsu";     /* in zephyr/dts/rx/renesas/rx130-common.dtsi:869 */
			reg = < 0xa0900 0x100 >;            /* in zephyr/dts/rx/renesas/rx130-common.dtsi:870 */
			clocks = < &pclkb 0x3 0xa >;        /* in zephyr/dts/rx/renesas/rx130-common.dtsi:871 */
			interrupts = < 0x3c 0x1 >,
			             < 0x3d 0x1 >,
			             < 0x3e 0x1 >;          /* in zephyr/dts/rx/renesas/rx130-common.dtsi:872 */
			interrupt-names = "ctsuwr",
			                  "ctsurd",
			                  "ctsufn";         /* in zephyr/dts/rx/renesas/rx130-common.dtsi:873 */
			pinctrl-0 = < &ctsu_default >;      /* in zephyr/boards/renesas/rsk_rx130/rsk_rx130.dts:126 */
			pinctrl-names = "default";          /* in zephyr/boards/renesas/rsk_rx130/rsk_rx130.dts:127 */
			max-num-sensors = < 0x24 >;         /* in zephyr/boards/renesas/rsk_rx130/rsk_rx130.dts:128 */
			tscap-gpios = < &ioportc 0x4 0x0 >; /* in zephyr/boards/renesas/rsk_rx130/rsk_rx130.dts:129 */
			status = "okay";                    /* in zephyr/boards/renesas/rsk_rx130/rsk_rx130.dts:130 */

			/* node '/soc/ctsu@a0900/touch_slider_0' defined in zephyr/boards/renesas/rsk_rx130/rsk_rx130.dts:132 */
			onboard_slider: touch_slider_0 {
				component-type = "slider";         /* in zephyr/boards/renesas/rsk_rx130/rsk_rx130.dts:133 */
				ssdiv = < 0x1 >;                   /* in zephyr/boards/renesas/rsk_rx130/rsk_rx130.dts:134 */
				so = < 0x40 >;                     /* in zephyr/boards/renesas/rsk_rx130/rsk_rx130.dts:135 */
				snum = < 0x3 >;                    /* in zephyr/boards/renesas/rsk_rx130/rsk_rx130.dts:136 */
				sdpa = < 0x7 >;                    /* in zephyr/boards/renesas/rsk_rx130/rsk_rx130.dts:137 */
				channels-num = < 0xa >,
				               < 0x9 >,
				               < 0x8 >,
				               < 0x7 >;            /* in zephyr/boards/renesas/rsk_rx130/rsk_rx130.dts:138 */
				zephyr,code = < 0x6 >;             /* in zephyr/boards/renesas/rsk_rx130/rsk_rx130.dts:139 */
				touch-count-threshold = < 0x2ee >; /* in zephyr/boards/renesas/rsk_rx130/rsk_rx130.dts:140 */

				/* node '/soc/ctsu@a0900/touch_slider_0/sld0' defined in zephyr/boards/renesas/rsk_rx130/rsk_rx130.dts:142 */
				sld0 {
					compatible = "renesas,rx-ctsu-slider"; /* in zephyr/boards/renesas/rsk_rx130/rsk_rx130.dts:143 */
					status = "okay";                       /* in zephyr/boards/renesas/rsk_rx130/rsk_rx130.dts:144 */
				};
			};

			/* node '/soc/ctsu@a0900/touch_button_1' defined in zephyr/boards/renesas/rsk_rx130/rsk_rx130.dts:148 */
			onboard_button_1: touch_button_1 {
				component-type = "button"; /* in zephyr/boards/renesas/rsk_rx130/rsk_rx130.dts:149 */
				ssdiv = < 0x0 >;           /* in zephyr/boards/renesas/rsk_rx130/rsk_rx130.dts:150 */
				snum = < 0x7 >;            /* in zephyr/boards/renesas/rsk_rx130/rsk_rx130.dts:151 */
				sdpa = < 0x3 >;            /* in zephyr/boards/renesas/rsk_rx130/rsk_rx130.dts:152 */
				channels-num = < 0xb >;    /* in zephyr/boards/renesas/rsk_rx130/rsk_rx130.dts:153 */
				zephyr,code = < 0x2 >;     /* in zephyr/boards/renesas/rsk_rx130/rsk_rx130.dts:154 */

				/* node '/soc/ctsu@a0900/touch_button_1/button1' defined in zephyr/boards/renesas/rsk_rx130/rsk_rx130.dts:156 */
				button1 {
					compatible = "renesas,rx-ctsu-button"; /* in zephyr/boards/renesas/rsk_rx130/rsk_rx130.dts:157 */
					status = "okay";                       /* in zephyr/boards/renesas/rsk_rx130/rsk_rx130.dts:158 */
				};
			};

			/* node '/soc/ctsu@a0900/touch_button_2' defined in zephyr/boards/renesas/rsk_rx130/rsk_rx130.dts:162 */
			onboard_button_2: touch_button_2 {
				component-type = "button"; /* in zephyr/boards/renesas/rsk_rx130/rsk_rx130.dts:163 */
				ssdiv = < 0x0 >;           /* in zephyr/boards/renesas/rsk_rx130/rsk_rx130.dts:164 */
				snum = < 0x7 >;            /* in zephyr/boards/renesas/rsk_rx130/rsk_rx130.dts:165 */
				sdpa = < 0x3 >;            /* in zephyr/boards/renesas/rsk_rx130/rsk_rx130.dts:166 */
				channels-num = < 0xc >;    /* in zephyr/boards/renesas/rsk_rx130/rsk_rx130.dts:167 */
				zephyr,code = < 0x3 >;     /* in zephyr/boards/renesas/rsk_rx130/rsk_rx130.dts:168 */

				/* node '/soc/ctsu@a0900/touch_button_2/button2' defined in zephyr/boards/renesas/rsk_rx130/rsk_rx130.dts:170 */
				button2 {
					compatible = "renesas,rx-ctsu-button"; /* in zephyr/boards/renesas/rsk_rx130/rsk_rx130.dts:171 */
					status = "okay";                       /* in zephyr/boards/renesas/rsk_rx130/rsk_rx130.dts:172 */
				};
			};
		};

		/* node '/soc/lvd@800e0' defined in zephyr/dts/rx/renesas/rx130-common.dtsi:877 */
		lvd0: lvd@800e0 {
			compatible = "renesas,rx-lvd"; /* in zephyr/dts/rx/renesas/rx130-common.dtsi:878 */
			reg = < 0x800e0 0x2 >;         /* in zephyr/dts/rx/renesas/rx130-common.dtsi:879 */
			channel = < 0x0 >;             /* in zephyr/dts/rx/renesas/rx130-common.dtsi:880 */
			interrupts = < 0x58 0x1 >;     /* in zephyr/dts/rx/renesas/rx130-common.dtsi:881 */
			interrupt-names = "lvd";       /* in zephyr/dts/rx/renesas/rx130-common.dtsi:882 */
			status = "disabled";           /* in zephyr/dts/rx/renesas/rx130-common.dtsi:883 */
		};

		/* node '/soc/lvd@800e2' defined in zephyr/dts/rx/renesas/rx130-common.dtsi:886 */
		lvd1: lvd@800e2 {
			compatible = "renesas,rx-lvd"; /* in zephyr/dts/rx/renesas/rx130-common.dtsi:887 */
			reg = < 0x800e2 0x2 >;         /* in zephyr/dts/rx/renesas/rx130-common.dtsi:888 */
			channel = < 0x1 >;             /* in zephyr/dts/rx/renesas/rx130-common.dtsi:889 */
			interrupts = < 0x59 0x1 >;     /* in zephyr/dts/rx/renesas/rx130-common.dtsi:890 */
			interrupt-names = "lvd";       /* in zephyr/dts/rx/renesas/rx130-common.dtsi:891 */
			lvd-support-cmpa;              /* in zephyr/dts/rx/renesas/rx130-common.dtsi:892 */
			status = "disabled";           /* in zephyr/dts/rx/renesas/rx130-common.dtsi:893 */
		};

		/* node '/soc/ofsm@ffffff80' defined in zephyr/dts/rx/renesas/rx130-common.dtsi:896 */
		ofsm: ofsm@ffffff80 {
			compatible = "zephyr,memory-region"; /* in zephyr/dts/rx/renesas/rx130-common.dtsi:897 */
			reg = < 0xffffff80 0xf >;            /* in zephyr/dts/rx/renesas/rx130-common.dtsi:898 */
			zephyr,memory-region = "OFSM";       /* in zephyr/dts/rx/renesas/rx130-common.dtsi:899 */
			status = "okay";                     /* in zephyr/dts/rx/renesas/rx130-common.dtsi:900 */
		};

		/* node '/soc/watchdog@88030' defined in zephyr/dts/rx/renesas/rx130-common.dtsi:903 */
		iwdt: watchdog@88030 {
			compatible = "renesas,rx-iwdt";  /* in zephyr/dts/rx/renesas/rx130-common.dtsi:904 */
			reg = < 0x88030 0x10 >;          /* in zephyr/dts/rx/renesas/rx130-common.dtsi:905 */
			clocks = < &iwdtlsclk 0x0 0x0 >; /* in zephyr/dts/rx/renesas/rx130-common.dtsi:906 */
			window-start = < 0x3000 >;       /* in zephyr/boards/renesas/rsk_rx130/rsk_rx130.dts:211 */
			window-end = < 0x300 >;          /* in zephyr/boards/renesas/rsk_rx130/rsk_rx130.dts:212 */
			status = "okay";                 /* in zephyr/boards/renesas/rsk_rx130/rsk_rx130.dts:213 */
		};

		/* node '/soc/memory@0' defined in zephyr/dts/rx/renesas/r5f51308axfp.dtsi:152 */
		sram0: memory@0 {
			device_type = "memory";   /* in zephyr/dts/rx/renesas/r5f51308axfp.dtsi:153 */
			compatible = "mmio-sram"; /* in zephyr/dts/rx/renesas/r5f51308axfp.dtsi:154 */
			reg = < 0x0 0xc000 >;     /* in zephyr/dts/rx/renesas/r5f51308axfp.dtsi:155 */
		};

		/* node '/soc/flash-controller@7fc090' defined in zephyr/dts/rx/renesas/r5f51308axfp.dtsi:158 */
		flash: flash-controller@7fc090 {
			#address-cells = < 0x1 >;        /* in zephyr/dts/rx/renesas/r5f51308axfp.dtsi:159 */
			#size-cells = < 0x1 >;           /* in zephyr/dts/rx/renesas/r5f51308axfp.dtsi:160 */
			compatible = "renesas,rx-flash"; /* in zephyr/dts/rx/renesas/r5f51308axfp.dtsi:161 */
			reg = < 0x7fc090 0x3f24 >;       /* in zephyr/dts/rx/renesas/r5f51308axfp.dtsi:162 */
			interrupts = < 0x17 0x1 >;       /* in zephyr/dts/rx/renesas/r5f51308axfp.dtsi:163 */
			interrupt-names = "frdyi";       /* in zephyr/dts/rx/renesas/r5f51308axfp.dtsi:164 */

			/* node '/soc/flash-controller@7fc090/flash@fff80000' defined in zephyr/dts/rx/renesas/r5f51308axfp.dtsi:166 */
			code_flash: flash@fff80000 {
				compatible = "renesas,rx-nv-flash"; /* in zephyr/dts/rx/renesas/r5f51308axfp.dtsi:167 */
				reg = < 0xfff80000 0x80000 >;       /* in zephyr/dts/rx/renesas/r5f51308axfp.dtsi:168 */
				write-block-size = < 0x4 >;         /* in zephyr/dts/rx/renesas/r5f51308axfp.dtsi:169 */
				erase-block-size = < 0x400 >;       /* in zephyr/dts/rx/renesas/r5f51308axfp.dtsi:170 */
			};

			/* node '/soc/flash-controller@7fc090/flash@100000' defined in zephyr/dts/rx/renesas/r5f51308axfp.dtsi:173 */
			data_flash: flash@100000 {
				compatible = "renesas,rx-nv-flash"; /* in zephyr/dts/rx/renesas/r5f51308axfp.dtsi:174 */
				bgo-enable;                         /* in zephyr/dts/rx/renesas/r5f51308axfp.dtsi:175 */
				reg = < 0x100000 0x2000 >;          /* in zephyr/dts/rx/renesas/r5f51308axfp.dtsi:176 */
				write-block-size = < 0x1 >;         /* in zephyr/dts/rx/renesas/r5f51308axfp.dtsi:177 */
				erase-block-size = < 0x400 >;       /* in zephyr/dts/rx/renesas/r5f51308axfp.dtsi:178 */

				/* node '/soc/flash-controller@7fc090/flash@100000/partitions' defined in zephyr/boards/renesas/rsk_rx130/rsk_rx130.dts:192 */
				partitions {
					compatible = "fixed-partitions"; /* in zephyr/boards/renesas/rsk_rx130/rsk_rx130.dts:193 */
					#address-cells = < 0x1 >;        /* in zephyr/boards/renesas/rsk_rx130/rsk_rx130.dts:194 */
					#size-cells = < 0x1 >;           /* in zephyr/boards/renesas/rsk_rx130/rsk_rx130.dts:195 */

					/* node '/soc/flash-controller@7fc090/flash@100000/partitions/partition@0' defined in zephyr/boards/renesas/rsk_rx130/rsk_rx130.dts:197 */
					storage_partition: partition@0 {
						label = "storage";    /* in zephyr/boards/renesas/rsk_rx130/rsk_rx130.dts:198 */
						reg = < 0x0 0x2000 >; /* in zephyr/boards/renesas/rsk_rx130/rsk_rx130.dts:199 */
					};
				};
			};
		};
	};

	/* node '/clocks' defined in zephyr/dts/rx/renesas/r5f51308axfp.dtsi:11 */
	clocks: clocks {
		#address-cells = < 0x1 >; /* in zephyr/dts/rx/renesas/r5f51308axfp.dtsi:12 */
		#size-cells = < 0x1 >;    /* in zephyr/dts/rx/renesas/r5f51308axfp.dtsi:13 */

		/* node '/clocks/clock-main-osc' defined in zephyr/dts/rx/renesas/r5f51308axfp.dtsi:15 */
		xtal: clock-main-osc {
			compatible = "renesas,rx-cgc-root-clock"; /* in zephyr/dts/rx/renesas/r5f51308axfp.dtsi:16 */
			stabilization-time = < 0x4 >;             /* in zephyr/dts/rx/renesas/r5f51308axfp.dtsi:19 */
			clock-frequency = < 0x7a1200 >;           /* in zephyr/boards/renesas/rsk_rx130/rsk_rx130.dts:60 */
			mosel = < 0x0 >;                          /* in zephyr/boards/renesas/rsk_rx130/rsk_rx130.dts:61 */
			#clock-cells = < 0x0 >;                   /* in zephyr/boards/renesas/rsk_rx130/rsk_rx130.dts:62 */
			status = "okay";                          /* in zephyr/boards/renesas/rsk_rx130/rsk_rx130.dts:63 */
			phandle = < 0x24 >;                       /* in zephyr/dts/rx/renesas/r5f51308axfp.dtsi:57 */
		};

		/* node '/clocks/clock-hoco' defined in zephyr/dts/rx/renesas/r5f51308axfp.dtsi:24 */
		hoco: clock-hoco {
			compatible = "renesas,rx-cgc-root-clock"; /* in zephyr/dts/rx/renesas/r5f51308axfp.dtsi:25 */
			clock-frequency = < 0x1e84800 >;          /* in zephyr/dts/rx/renesas/r5f51308axfp.dtsi:26 */
			#clock-cells = < 0x0 >;                   /* in zephyr/dts/rx/renesas/r5f51308axfp.dtsi:27 */
			status = "okay";                          /* in zephyr/dts/rx/renesas/r5f51308axfp.dtsi:28 */
			phandle = < 0x28 >;                       /* in zephyr/dts/rx/renesas/r5f51308axfp.dtsi:131 */
		};

		/* node '/clocks/clock-loco' defined in zephyr/dts/rx/renesas/r5f51308axfp.dtsi:31 */
		loco: clock-loco {
			compatible = "renesas,rx-cgc-root-clock"; /* in zephyr/dts/rx/renesas/r5f51308axfp.dtsi:32 */
			clock-frequency = < 0x3d0900 >;           /* in zephyr/dts/rx/renesas/r5f51308axfp.dtsi:33 */
			#clock-cells = < 0x0 >;                   /* in zephyr/dts/rx/renesas/r5f51308axfp.dtsi:34 */
			status = "okay";                          /* in zephyr/dts/rx/renesas/r5f51308axfp.dtsi:35 */
			phandle = < 0x27 >;                       /* in zephyr/dts/rx/renesas/r5f51308axfp.dtsi:117 */
		};

		/* node '/clocks/clock-subclk' defined in zephyr/dts/rx/renesas/r5f51308axfp.dtsi:38 */
		subclk: clock-subclk {
			compatible = "renesas,rx-cgc-root-clock"; /* in zephyr/dts/rx/renesas/r5f51308axfp.dtsi:39 */
			clock-frequency = < 0x8000 >;             /* in zephyr/dts/rx/renesas/r5f51308axfp.dtsi:40 */
			drive-capacity = < 0x0 >;                 /* in zephyr/dts/rx/renesas/r5f51308axfp.dtsi:41 */
			#clock-cells = < 0x0 >;                   /* in zephyr/dts/rx/renesas/r5f51308axfp.dtsi:42 */
			status = "okay";                          /* in zephyr/boards/renesas/rsk_rx130/rsk_rx130.dts:67 */
			phandle = < 0x26 >;                       /* in zephyr/dts/rx/renesas/r5f51308axfp.dtsi:110 */
		};

		/* node '/clocks/clock-iwdt-low-speed' defined in zephyr/dts/rx/renesas/r5f51308axfp.dtsi:46 */
		iwdtlsclk: clock-iwdt-low-speed {
			compatible = "renesas,rx-cgc-root-clock"; /* in zephyr/dts/rx/renesas/r5f51308axfp.dtsi:47 */
			clock-frequency = < 0x3a98 >;             /* in zephyr/dts/rx/renesas/r5f51308axfp.dtsi:48 */
			#clock-cells = < 0x0 >;                   /* in zephyr/dts/rx/renesas/r5f51308axfp.dtsi:49 */
			status = "okay";                          /* in zephyr/boards/renesas/rsk_rx130/rsk_rx130.dts:77 */
			phandle = < 0x23 >;                       /* in zephyr/dts/rx/renesas/rx130-common.dtsi:906 */
		};

		/* node '/clocks/pll' defined in zephyr/dts/rx/renesas/r5f51308axfp.dtsi:53 */
		pll: pll {
			compatible = "renesas,rx-cgc-pll"; /* in zephyr/dts/rx/renesas/r5f51308axfp.dtsi:54 */
			#clock-cells = < 0x0 >;            /* in zephyr/dts/rx/renesas/r5f51308axfp.dtsi:55 */
			clocks = < &xtal >;                /* in zephyr/dts/rx/renesas/r5f51308axfp.dtsi:57 */
			div = < 0x2 >;                     /* in zephyr/boards/renesas/rsk_rx130/rsk_rx130.dts:71 */
			mul = < 0xf >;                     /* in zephyr/boards/renesas/rsk_rx130/rsk_rx130.dts:72 */
			status = "okay";                   /* in zephyr/boards/renesas/rsk_rx130/rsk_rx130.dts:73 */
			phandle = < 0x25 >;                /* in zephyr/dts/rx/renesas/r5f51308axfp.dtsi:68 */
		};

		/* node '/clocks/pclkblock@80010' defined in zephyr/dts/rx/renesas/r5f51308axfp.dtsi:62 */
		pclkblock: pclkblock@80010 {
			compatible = "renesas,rx-cgc-pclk-block"; /* in zephyr/dts/rx/renesas/r5f51308axfp.dtsi:63 */
			reg = < 0x80010 0x4 >,
			      < 0x80014 0x4 >,
			      < 0x80018 0x4 >,
			      < 0x8001c 0x4 >;                    /* in zephyr/dts/rx/renesas/r5f51308axfp.dtsi:64 */
			reg-names = "MSTPA",
			            "MSTPB",
			            "MSTPC",
			            "MSTPD";                      /* in zephyr/dts/rx/renesas/r5f51308axfp.dtsi:66 */
			#clock-cells = < 0x0 >;                   /* in zephyr/dts/rx/renesas/r5f51308axfp.dtsi:67 */
			clocks = < &pll >;                        /* in zephyr/dts/rx/renesas/r5f51308axfp.dtsi:68 */
			status = "okay";                          /* in zephyr/dts/rx/renesas/r5f51308axfp.dtsi:69 */

			/* node '/clocks/pclkblock@80010/iclk' defined in zephyr/dts/rx/renesas/r5f51308axfp.dtsi:71 */
			iclk: iclk {
				compatible = "renesas,rx-cgc-pclk"; /* in zephyr/dts/rx/renesas/r5f51308axfp.dtsi:72 */
				div = < 0x1 >;                      /* in zephyr/dts/rx/renesas/r5f51308axfp.dtsi:73 */
				#clock-cells = < 0x2 >;             /* in zephyr/dts/rx/renesas/r5f51308axfp.dtsi:74 */
				status = "okay";                    /* in zephyr/dts/rx/renesas/r5f51308axfp.dtsi:75 */
				phandle = < 0x4 >;                  /* in zephyr/dts/rx/renesas/rx130-common.dtsi:79 */
			};

			/* node '/clocks/pclkblock@80010/fclk' defined in zephyr/dts/rx/renesas/r5f51308axfp.dtsi:78 */
			fclk: fclk {
				compatible = "renesas,rx-cgc-pclk"; /* in zephyr/dts/rx/renesas/r5f51308axfp.dtsi:79 */
				div = < 0x1 >;                      /* in zephyr/dts/rx/renesas/r5f51308axfp.dtsi:80 */
				#clock-cells = < 0x2 >;             /* in zephyr/dts/rx/renesas/r5f51308axfp.dtsi:81 */
				status = "okay";                    /* in zephyr/dts/rx/renesas/r5f51308axfp.dtsi:82 */
			};

			/* node '/clocks/pclkblock@80010/pclkb' defined in zephyr/dts/rx/renesas/r5f51308axfp.dtsi:85 */
			pclkb: pclkb {
				compatible = "renesas,rx-cgc-pclk"; /* in zephyr/dts/rx/renesas/r5f51308axfp.dtsi:86 */
				div = < 0x1 >;                      /* in zephyr/dts/rx/renesas/r5f51308axfp.dtsi:87 */
				#clock-cells = < 0x2 >;             /* in zephyr/dts/rx/renesas/r5f51308axfp.dtsi:88 */
				status = "okay";                    /* in zephyr/dts/rx/renesas/r5f51308axfp.dtsi:89 */
				phandle = < 0x1a >;                 /* in zephyr/dts/rx/renesas/rx130-common.dtsi:570 */
			};

			/* node '/clocks/pclkblock@80010/pclkd' defined in zephyr/dts/rx/renesas/r5f51308axfp.dtsi:92 */
			pclkd: pclkd {
				compatible = "renesas,rx-cgc-pclk"; /* in zephyr/dts/rx/renesas/r5f51308axfp.dtsi:93 */
				div = < 0x1 >;                      /* in zephyr/dts/rx/renesas/r5f51308axfp.dtsi:94 */
				#clock-cells = < 0x2 >;             /* in zephyr/dts/rx/renesas/r5f51308axfp.dtsi:95 */
				status = "okay";                    /* in zephyr/dts/rx/renesas/r5f51308axfp.dtsi:96 */
			};
		};

		/* node '/clocks/clkout' defined in zephyr/dts/rx/renesas/r5f51308axfp.dtsi:100 */
		clkout: clkout {
			compatible = "renesas,rx-cgc-pclk"; /* in zephyr/dts/rx/renesas/r5f51308axfp.dtsi:101 */
			clocks = < &xtal >;                 /* in zephyr/dts/rx/renesas/r5f51308axfp.dtsi:102 */
			div = < 0x1 >;                      /* in zephyr/dts/rx/renesas/r5f51308axfp.dtsi:103 */
			#clock-cells = < 0x2 >;             /* in zephyr/dts/rx/renesas/r5f51308axfp.dtsi:104 */
			status = "disabled";                /* in zephyr/dts/rx/renesas/r5f51308axfp.dtsi:105 */
		};

		/* node '/clocks/rtcsclk' defined in zephyr/dts/rx/renesas/r5f51308axfp.dtsi:108 */
		rtcsclk: rtcsclk {
			compatible = "renesas,rx-cgc-pclk"; /* in zephyr/dts/rx/renesas/r5f51308axfp.dtsi:109 */
			clocks = < &subclk >;               /* in zephyr/dts/rx/renesas/r5f51308axfp.dtsi:110 */
			#clock-cells = < 0x2 >;             /* in zephyr/dts/rx/renesas/r5f51308axfp.dtsi:111 */
			status = "disabled";                /* in zephyr/dts/rx/renesas/r5f51308axfp.dtsi:112 */
		};

		/* node '/clocks/caclclk' defined in zephyr/dts/rx/renesas/r5f51308axfp.dtsi:115 */
		caclclk: caclclk {
			compatible = "renesas,rx-cgc-pclk"; /* in zephyr/dts/rx/renesas/r5f51308axfp.dtsi:116 */
			clocks = < &loco >;                 /* in zephyr/dts/rx/renesas/r5f51308axfp.dtsi:117 */
			#clock-cells = < 0x2 >;             /* in zephyr/dts/rx/renesas/r5f51308axfp.dtsi:118 */
			status = "disabled";                /* in zephyr/dts/rx/renesas/r5f51308axfp.dtsi:119 */
		};

		/* node '/clocks/cacmclk' defined in zephyr/dts/rx/renesas/r5f51308axfp.dtsi:122 */
		cacmclk: cacmclk {
			compatible = "renesas,rx-cgc-pclk"; /* in zephyr/dts/rx/renesas/r5f51308axfp.dtsi:123 */
			clocks = < &xtal >;                 /* in zephyr/dts/rx/renesas/r5f51308axfp.dtsi:124 */
			#clock-cells = < 0x2 >;             /* in zephyr/dts/rx/renesas/r5f51308axfp.dtsi:125 */
			status = "disabled";                /* in zephyr/dts/rx/renesas/r5f51308axfp.dtsi:126 */
		};

		/* node '/clocks/cachclk' defined in zephyr/dts/rx/renesas/r5f51308axfp.dtsi:129 */
		cachclk: cachclk {
			compatible = "renesas,rx-cgc-pclk"; /* in zephyr/dts/rx/renesas/r5f51308axfp.dtsi:130 */
			clocks = < &hoco >;                 /* in zephyr/dts/rx/renesas/r5f51308axfp.dtsi:131 */
			#clock-cells = < 0x2 >;             /* in zephyr/dts/rx/renesas/r5f51308axfp.dtsi:132 */
			status = "disabled";                /* in zephyr/dts/rx/renesas/r5f51308axfp.dtsi:133 */
		};

		/* node '/clocks/cacsclk' defined in zephyr/dts/rx/renesas/r5f51308axfp.dtsi:136 */
		cacsclk: cacsclk {
			compatible = "renesas,rx-cgc-pclk"; /* in zephyr/dts/rx/renesas/r5f51308axfp.dtsi:137 */
			clocks = < &subclk >;               /* in zephyr/dts/rx/renesas/r5f51308axfp.dtsi:138 */
			#clock-cells = < 0x2 >;             /* in zephyr/dts/rx/renesas/r5f51308axfp.dtsi:139 */
			status = "disabled";                /* in zephyr/dts/rx/renesas/r5f51308axfp.dtsi:140 */
		};

		/* node '/clocks/iwdtclk' defined in zephyr/dts/rx/renesas/r5f51308axfp.dtsi:143 */
		iwdtclk: iwdtclk {
			compatible = "renesas,rx-cgc-pclk"; /* in zephyr/dts/rx/renesas/r5f51308axfp.dtsi:144 */
			clocks = < &iwdtlsclk >;            /* in zephyr/dts/rx/renesas/r5f51308axfp.dtsi:145 */
			#clock-cells = < 0x2 >;             /* in zephyr/dts/rx/renesas/r5f51308axfp.dtsi:146 */
			status = "disabled";                /* in zephyr/dts/rx/renesas/r5f51308axfp.dtsi:147 */
		};
	};

	/* node '/chosen' defined in zephyr/boards/renesas/rsk_rx130/rsk_rx130.dts:19 */
	chosen {
		zephyr,sram = &sram0;             /* in zephyr/boards/renesas/rsk_rx130/rsk_rx130.dts:20 */
		zephyr,flash = &code_flash;       /* in zephyr/boards/renesas/rsk_rx130/rsk_rx130.dts:21 */
		zephyr,flash-controller = &flash; /* in zephyr/boards/renesas/rsk_rx130/rsk_rx130.dts:22 */
		zephyr,console = &uart1;          /* in zephyr/boards/renesas/rsk_rx130/rsk_rx130.dts:23 */
		zephyr,shell-uart = &uart1;       /* in zephyr/boards/renesas/rsk_rx130/rsk_rx130.dts:24 */
	};

	/* node '/leds' defined in zephyr/boards/renesas/rsk_rx130/rsk_rx130.dts:27 */
	leds {
		compatible = "gpio-leds"; /* in zephyr/boards/renesas/rsk_rx130/rsk_rx130.dts:28 */

		/* node '/leds/led1' defined in zephyr/boards/renesas/rsk_rx130/rsk_rx130.dts:30 */
		led1: led1 {
			gpios = < &ioportd 0x3 0x1 >; /* in zephyr/boards/renesas/rsk_rx130/rsk_rx130.dts:31 */
			label = "LED1";               /* in zephyr/boards/renesas/rsk_rx130/rsk_rx130.dts:32 */
		};

		/* node '/leds/led3' defined in zephyr/boards/renesas/rsk_rx130/rsk_rx130.dts:35 */
		led3: led3 {
			gpios = < &ioporte 0x6 0x1 >; /* in zephyr/boards/renesas/rsk_rx130/rsk_rx130.dts:36 */
			label = "LED3";               /* in zephyr/boards/renesas/rsk_rx130/rsk_rx130.dts:37 */
		};
	};

	/* node '/buttons' defined in zephyr/boards/renesas/rsk_rx130/rsk_rx130.dts:41 */
	buttons {
		compatible = "gpio-keys"; /* in zephyr/boards/renesas/rsk_rx130/rsk_rx130.dts:42 */

		/* node '/buttons/button' defined in zephyr/boards/renesas/rsk_rx130/rsk_rx130.dts:44 */
		sw1: button {
			label = "sw1";                 /* in zephyr/boards/renesas/rsk_rx130/rsk_rx130.dts:45 */
			gpios = < &ioport3 0x1 0x11 >; /* in zephyr/boards/renesas/rsk_rx130/rsk_rx130.dts:46 */
			zephyr,code = < 0xb >;         /* in zephyr/boards/renesas/rsk_rx130/rsk_rx130.dts:47 */
		};
	};

	/* node '/aliases' defined in zephyr/boards/renesas/rsk_rx130/rsk_rx130.dts:51 */
	aliases {
		led0 = &led1;      /* in zephyr/boards/renesas/rsk_rx130/rsk_rx130.dts:52 */
		led1 = &led3;      /* in zephyr/boards/renesas/rsk_rx130/rsk_rx130.dts:53 */
		sw0 = &sw1;        /* in zephyr/boards/renesas/rsk_rx130/rsk_rx130.dts:54 */
		watchdog0 = &iwdt; /* in zephyr/boards/renesas/rsk_rx130/rsk_rx130.dts:55 */
	};
};
